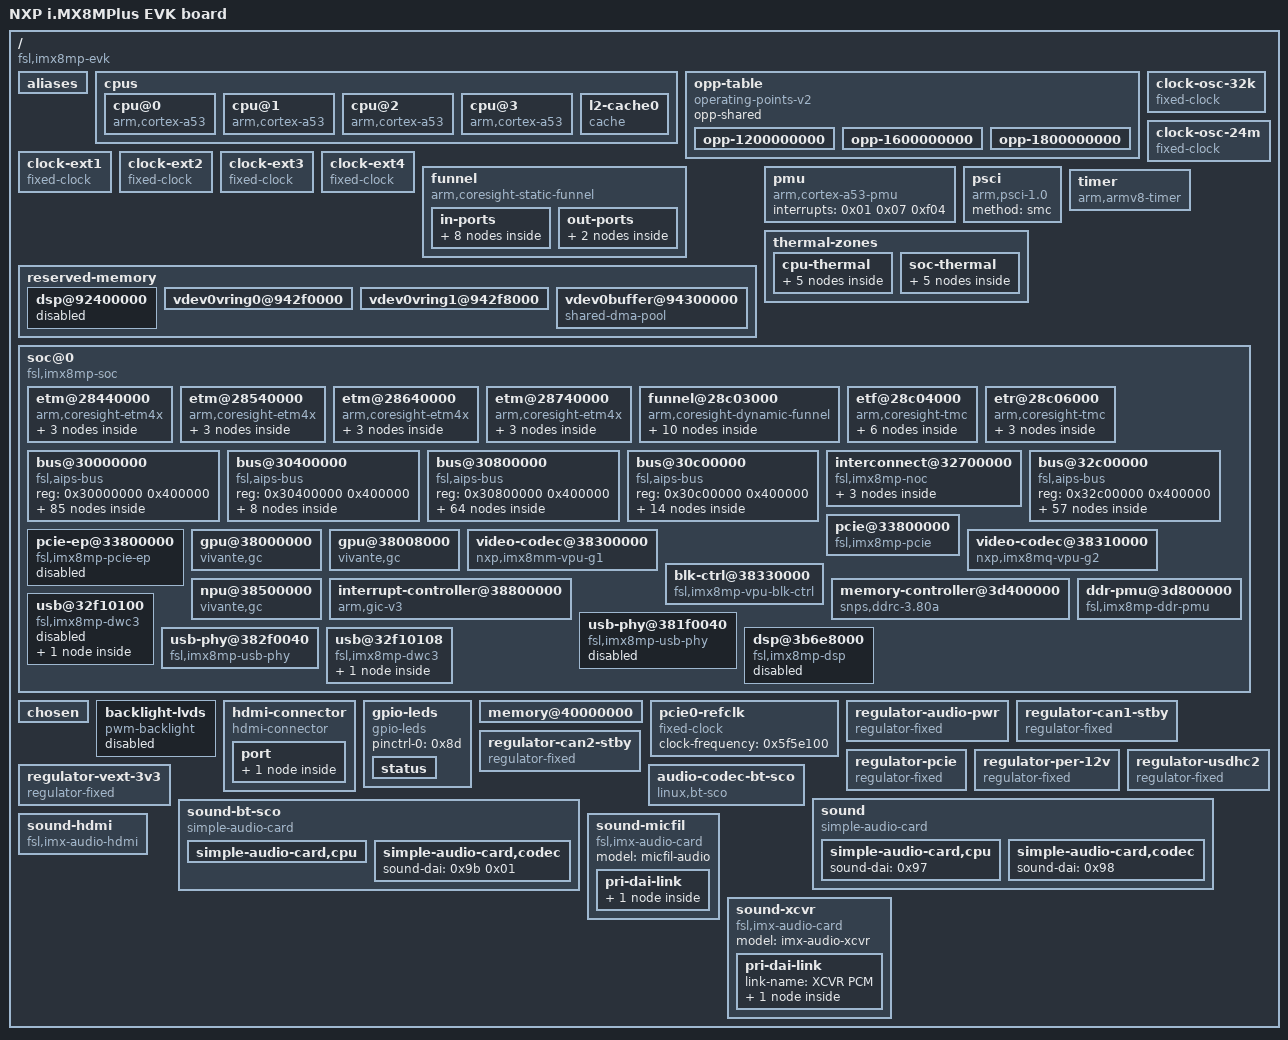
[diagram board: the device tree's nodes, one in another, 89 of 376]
/*
 * Copyright Linux Kernel Team
 *
 * SPDX-License-Identifier: GPL-2.0-only
 *
 * This file is derived from an intermediate build stage of the
 * Linux kernel. The licenses of all input files to this process
 * are compatible with GPL-2.0-only.
 */
/dts-v1/;

/ {
	interrupt-parent = <0x01>;
	#address-cells = <0x02>;
	#size-cells = <0x02>;
	model = "NXP i.MX8MPlus EVK board";
	compatible = "fsl,imx8mp-evk", "fsl,imx8mp";

	aliases {
		ethernet0 = "/soc@0/bus@30800000/ethernet@30be0000";
		ethernet1 = "/soc@0/bus@30800000/ethernet@30bf0000";
		gpio0 = "/soc@0/bus@30000000/gpio@30200000";
		gpio1 = "/soc@0/bus@30000000/gpio@30210000";
		gpio2 = "/soc@0/bus@30000000/gpio@30220000";
		gpio3 = "/soc@0/bus@30000000/gpio@30230000";
		gpio4 = "/soc@0/bus@30000000/gpio@30240000";
		i2c0 = "/soc@0/bus@30800000/i2c@30a20000";
		i2c1 = "/soc@0/bus@30800000/i2c@30a30000";
		i2c2 = "/soc@0/bus@30800000/i2c@30a40000";
		i2c3 = "/soc@0/bus@30800000/i2c@30a50000";
		i2c4 = "/soc@0/bus@30800000/i2c@30ad0000";
		i2c5 = "/soc@0/bus@30800000/i2c@30ae0000";
		mmc0 = "/soc@0/bus@30800000/mmc@30b40000";
		mmc1 = "/soc@0/bus@30800000/mmc@30b50000";
		mmc2 = "/soc@0/bus@30800000/mmc@30b60000";
		serial0 = "/soc@0/bus@30800000/spba-bus@30800000/serial@30860000";
		serial1 = "/soc@0/bus@30800000/spba-bus@30800000/serial@30890000";
		serial2 = "/soc@0/bus@30800000/spba-bus@30800000/serial@30880000";
		serial3 = "/soc@0/bus@30800000/serial@30a60000";
		spi0 = "/soc@0/bus@30800000/spi@30bb0000";
	};

	cpus {
		#address-cells = <0x01>;
		#size-cells = <0x00>;

		cpu@0 {
			device_type = "cpu";
			compatible = "arm,cortex-a53";
			reg = <0x00>;
			clock-latency = <0xee6c>;
			clocks = <0x02 0x11f>;
			enable-method = "psci";
			i-cache-size = <0x8000>;
			i-cache-line-size = <0x40>;
			i-cache-sets = <0x100>;
			d-cache-size = <0x8000>;
			d-cache-line-size = <0x40>;
			d-cache-sets = <0x80>;
			next-level-cache = <0x03>;
			nvmem-cells = <0x04>;
			nvmem-cell-names = "speed_grade";
			operating-points-v2 = <0x05>;
			#cooling-cells = <0x02>;
			cpu-supply = <0x06>;
			phandle = <0x0e>;
		};

		cpu@1 {
			device_type = "cpu";
			compatible = "arm,cortex-a53";
			reg = <0x01>;
			clock-latency = <0xee6c>;
			clocks = <0x02 0x11f>;
			enable-method = "psci";
			i-cache-size = <0x8000>;
			i-cache-line-size = <0x40>;
			i-cache-sets = <0x100>;
			d-cache-size = <0x8000>;
			d-cache-line-size = <0x40>;
			d-cache-sets = <0x80>;
			next-level-cache = <0x03>;
			operating-points-v2 = <0x05>;
			#cooling-cells = <0x02>;
			cpu-supply = <0x06>;
			phandle = <0x0f>;
		};

		cpu@2 {
			device_type = "cpu";
			compatible = "arm,cortex-a53";
			reg = <0x02>;
			clock-latency = <0xee6c>;
			clocks = <0x02 0x11f>;
			enable-method = "psci";
			i-cache-size = <0x8000>;
			i-cache-line-size = <0x40>;
			i-cache-sets = <0x100>;
			d-cache-size = <0x8000>;
			d-cache-line-size = <0x40>;
			d-cache-sets = <0x80>;
			next-level-cache = <0x03>;
			operating-points-v2 = <0x05>;
			#cooling-cells = <0x02>;
			cpu-supply = <0x06>;
			phandle = <0x10>;
		};

		cpu@3 {
			device_type = "cpu";
			compatible = "arm,cortex-a53";
			reg = <0x03>;
			clock-latency = <0xee6c>;
			clocks = <0x02 0x11f>;
			enable-method = "psci";
			i-cache-size = <0x8000>;
			i-cache-line-size = <0x40>;
			i-cache-sets = <0x100>;
			d-cache-size = <0x8000>;
			d-cache-line-size = <0x40>;
			d-cache-sets = <0x80>;
			next-level-cache = <0x03>;
			operating-points-v2 = <0x05>;
			#cooling-cells = <0x02>;
			cpu-supply = <0x06>;
			phandle = <0x11>;
		};

		l2-cache0 {
			compatible = "cache";
			cache-unified;
			cache-level = <0x02>;
			cache-size = <0x80000>;
			cache-line-size = <0x40>;
			cache-sets = <0x200>;
			phandle = <0x03>;
		};
	};

	opp-table {
		compatible = "operating-points-v2";
		opp-shared;
		phandle = <0x05>;

		opp-1200000000 {
			opp-hz = <0x00 0x47868c00>;
			opp-microvolt = <0xcf850>;
			opp-supported-hw = <0x8a0 0x07>;
			clock-latency-ns = <0x249f0>;
			opp-suspend;
		};

		opp-1600000000 {
			opp-hz = <0x00 0x5f5e1000>;
			opp-microvolt = <0xe7ef0>;
			opp-supported-hw = <0xa0 0x07>;
			clock-latency-ns = <0x249f0>;
			opp-suspend;
		};

		opp-1800000000 {
			opp-hz = <0x00 0x6b49d200>;
			opp-microvolt = <0xf4240>;
			opp-supported-hw = <0x20 0x03>;
			clock-latency-ns = <0x249f0>;
			opp-suspend;
		};
	};

	clock-osc-32k {
		compatible = "fixed-clock";
		#clock-cells = <0x00>;
		clock-frequency = <0x8000>;
		clock-output-names = "osc_32k";
		phandle = <0x22>;
	};

	clock-osc-24m {
		compatible = "fixed-clock";
		#clock-cells = <0x00>;
		clock-frequency = <0x16e3600>;
		clock-output-names = "osc_24m";
		phandle = <0x23>;
	};

	clock-ext1 {
		compatible = "fixed-clock";
		#clock-cells = <0x00>;
		clock-frequency = <0x7ed6b40>;
		clock-output-names = "clk_ext1";
		phandle = <0x24>;
	};

	clock-ext2 {
		compatible = "fixed-clock";
		#clock-cells = <0x00>;
		clock-frequency = <0x7ed6b40>;
		clock-output-names = "clk_ext2";
		phandle = <0x25>;
	};

	clock-ext3 {
		compatible = "fixed-clock";
		#clock-cells = <0x00>;
		clock-frequency = <0x7ed6b40>;
		clock-output-names = "clk_ext3";
		phandle = <0x26>;
	};

	clock-ext4 {
		compatible = "fixed-clock";
		#clock-cells = <0x00>;
		clock-frequency = <0x7ed6b40>;
		clock-output-names = "clk_ext4";
		phandle = <0x27>;
	};

	funnel {
		compatible = "arm,coresight-static-funnel";

		in-ports {
			#address-cells = <0x01>;
			#size-cells = <0x00>;

			port@0 {
				reg = <0x00>;

				endpoint {
					remote-endpoint = <0x07>;
					phandle = <0x14>;
				};
			};

			port@1 {
				reg = <0x01>;

				endpoint {
					remote-endpoint = <0x08>;
					phandle = <0x15>;
				};
			};

			port@2 {
				reg = <0x02>;

				endpoint {
					remote-endpoint = <0x09>;
					phandle = <0x16>;
				};
			};

			port@3 {
				reg = <0x03>;

				endpoint {
					remote-endpoint = <0x0a>;
					phandle = <0x17>;
				};
			};
		};

		out-ports {

			port {

				endpoint {
					remote-endpoint = <0x0b>;
					phandle = <0x18>;
				};
			};
		};
	};

	reserved-memory {
		#address-cells = <0x02>;
		#size-cells = <0x02>;
		ranges;

		dsp@92400000 {
			reg = <0x00 0x92400000 0x00 0x2000000>;
			no-map;
			status = "disabled";
			phandle = <0x89>;
		};

		vdev0vring0@942f0000 {
			reg = <0x00 0x942f0000 0x00 0x8000>;
			no-map;
			phandle = <0x9f>;
		};

		vdev0vring1@942f8000 {
			reg = <0x00 0x942f8000 0x00 0x8000>;
			no-map;
			phandle = <0xa0>;
		};

		vdev0buffer@94300000 {
			compatible = "shared-dma-pool";
			reg = <0x00 0x94300000 0x00 0x100000>;
			no-map;
			phandle = <0xa1>;
		};
	};

	pmu {
		compatible = "arm,cortex-a53-pmu";
		interrupts = <0x01 0x07 0xf04>;
	};

	psci {
		compatible = "arm,psci-1.0";
		method = "smc";
	};

	thermal-zones {

		cpu-thermal {
			polling-delay-passive = <0xfa>;
			polling-delay = <0x7d0>;
			thermal-sensors = <0x0c 0x00>;

			trips {

				trip0 {
					temperature = <0x14c08>;
					hysteresis = <0x7d0>;
					type = "passive";
					phandle = <0x0d>;
				};

				trip1 {
					temperature = <0x17318>;
					hysteresis = <0x7d0>;
					type = "critical";
					phandle = <0xa2>;
				};
			};

			cooling-maps {

				map0 {
					trip = <0x0d>;
					cooling-device = <0x0e 0xffffffff 0xffffffff 0x0f 0xffffffff 0xffffffff 0x10 0xffffffff 0xffffffff 0x11 0xffffffff 0xffffffff>;
				};
			};
		};

		soc-thermal {
			polling-delay-passive = <0xfa>;
			polling-delay = <0x7d0>;
			thermal-sensors = <0x0c 0x01>;

			trips {

				trip0 {
					temperature = <0x14c08>;
					hysteresis = <0x7d0>;
					type = "passive";
					phandle = <0x12>;
				};

				trip1 {
					temperature = <0x17318>;
					hysteresis = <0x7d0>;
					type = "critical";
					phandle = <0xa3>;
				};
			};

			cooling-maps {

				map0 {
					trip = <0x12>;
					cooling-device = <0x0e 0xffffffff 0xffffffff 0x0f 0xffffffff 0xffffffff 0x10 0xffffffff 0xffffffff 0x11 0xffffffff 0xffffffff>;
				};
			};
		};
	};

	timer {
		compatible = "arm,armv8-timer";
		interrupts = <0x01 0x0d 0xf08 0x01 0x0e 0xf08 0x01 0x0b 0xf08 0x01 0x0a 0xf08>;
		clock-frequency = <0x7a1200>;
		arm,no-tick-in-suspend;
	};

	soc@0 {
		compatible = "fsl,imx8mp-soc", "simple-bus";
		#address-cells = <0x01>;
		#size-cells = <0x01>;
		ranges = <0x00 0x00 0x00 0x3e000000>;
		nvmem-cells = <0x13>;
		nvmem-cell-names = "soc_unique_id";
		phandle = <0xa4>;

		etm@28440000 {
			compatible = "arm,coresight-etm4x", "arm,primecell";
			reg = <0x28440000 0x1000>;
			cpu = <0x0e>;
			clocks = <0x02 0x5d>;
			clock-names = "apb_pclk";
			phandle = <0xa5>;

			out-ports {

				port {

					endpoint {
						remote-endpoint = <0x14>;
						phandle = <0x07>;
					};
				};
			};
		};

		etm@28540000 {
			compatible = "arm,coresight-etm4x", "arm,primecell";
			reg = <0x28540000 0x1000>;
			cpu = <0x0f>;
			clocks = <0x02 0x5d>;
			clock-names = "apb_pclk";
			phandle = <0xa6>;

			out-ports {

				port {

					endpoint {
						remote-endpoint = <0x15>;
						phandle = <0x08>;
					};
				};
			};
		};

		etm@28640000 {
			compatible = "arm,coresight-etm4x", "arm,primecell";
			reg = <0x28640000 0x1000>;
			cpu = <0x10>;
			clocks = <0x02 0x5d>;
			clock-names = "apb_pclk";
			phandle = <0xa7>;

			out-ports {

				port {

					endpoint {
						remote-endpoint = <0x16>;
						phandle = <0x09>;
					};
				};
			};
		};

		etm@28740000 {
			compatible = "arm,coresight-etm4x", "arm,primecell";
			reg = <0x28740000 0x1000>;
			cpu = <0x11>;
			clocks = <0x02 0x5d>;
			clock-names = "apb_pclk";
			phandle = <0xa8>;

			out-ports {

				port {

					endpoint {
						remote-endpoint = <0x17>;
						phandle = <0x0a>;
					};
				};
			};
		};

		funnel@28c03000 {
			compatible = "arm,coresight-dynamic-funnel", "arm,primecell";
			reg = <0x28c03000 0x1000>;
			clocks = <0x02 0x5d>;
			clock-names = "apb_pclk";

			in-ports {
				#address-cells = <0x01>;
				#size-cells = <0x00>;

				port@0 {
					reg = <0x00>;

					endpoint {
						remote-endpoint = <0x18>;
						phandle = <0x0b>;
					};
				};

				port@1 {
					reg = <0x01>;

					endpoint {
						phandle = <0xa9>;
					};
				};

				port@2 {
					reg = <0x02>;

					endpoint {
						phandle = <0xaa>;
					};
				};
			};

			out-ports {

				port {

					endpoint {
						remote-endpoint = <0x19>;
						phandle = <0x1a>;
					};
				};
			};
		};

		etf@28c04000 {
			compatible = "arm,coresight-tmc", "arm,primecell";
			reg = <0x28c04000 0x1000>;
			clocks = <0x02 0x5d>;
			clock-names = "apb_pclk";

			in-ports {

				port {

					endpoint {
						remote-endpoint = <0x1a>;
						phandle = <0x19>;
					};
				};
			};

			out-ports {

				port {

					endpoint {
						remote-endpoint = <0x1b>;
						phandle = <0x1c>;
					};
				};
			};
		};

		etr@28c06000 {
			compatible = "arm,coresight-tmc", "arm,primecell";
			reg = <0x28c06000 0x1000>;
			clocks = <0x02 0x5d>;
			clock-names = "apb_pclk";

			in-ports {

				port {

					endpoint {
						remote-endpoint = <0x1c>;
						phandle = <0x1b>;
					};
				};
			};
		};

		bus@30000000 {
			compatible = "fsl,aips-bus", "simple-bus";
			reg = <0x30000000 0x400000>;
			#address-cells = <0x01>;
			#size-cells = <0x01>;
			ranges;
			phandle = <0xab>;

			gpio@30200000 {
				compatible = "fsl,imx8mp-gpio", "fsl,imx35-gpio";
				reg = <0x30200000 0x10000>;
				interrupts = <0x00 0x40 0x04 0x00 0x41 0x04>;
				clocks = <0x02 0xc1>;
				gpio-controller;
				#gpio-cells = <0x02>;
				interrupt-controller;
				#interrupt-cells = <0x02>;
				gpio-ranges = <0x1d 0x00 0x05 0x1e>;
				phandle = <0x38>;
			};

			gpio@30210000 {
				compatible = "fsl,imx8mp-gpio", "fsl,imx35-gpio";
				reg = <0x30210000 0x10000>;
				interrupts = <0x00 0x42 0x04 0x00 0x43 0x04>;
				clocks = <0x02 0xc2>;
				gpio-controller;
				#gpio-cells = <0x02>;
				interrupt-controller;
				#interrupt-cells = <0x02>;
				gpio-ranges = <0x1d 0x00 0x23 0x15>;
				phandle = <0x47>;
			};

			gpio@30220000 {
				compatible = "fsl,imx8mp-gpio", "fsl,imx35-gpio";
				reg = <0x30220000 0x10000>;
				interrupts = <0x00 0x44 0x04 0x00 0x45 0x04>;
				clocks = <0x02 0xc3>;
				gpio-controller;
				#gpio-cells = <0x02>;
				interrupt-controller;
				#interrupt-cells = <0x02>;
				gpio-ranges = <0x1d 0x00 0x38 0x1a 0x1d 0x1a 0x90 0x04>;
				phandle = <0x8e>;
			};

			gpio@30230000 {
				compatible = "fsl,imx8mp-gpio", "fsl,imx35-gpio";
				reg = <0x30230000 0x10000>;
				interrupts = <0x00 0x46 0x04 0x00 0x47 0x04>;
				clocks = <0x02 0xc4>;
				gpio-controller;
				#gpio-cells = <0x02>;
				interrupt-controller;
				#interrupt-cells = <0x02>;
				gpio-ranges = <0x1d 0x00 0x52 0x20>;
				phandle = <0x50>;
			};

			gpio@30240000 {
				compatible = "fsl,imx8mp-gpio", "fsl,imx35-gpio";
				reg = <0x30240000 0x10000>;
				interrupts = <0x00 0x48 0x04 0x00 0x49 0x04>;
				clocks = <0x02 0xc5>;
				gpio-controller;
				#gpio-cells = <0x02>;
				interrupt-controller;
				#interrupt-cells = <0x02>;
				gpio-ranges = <0x1d 0x00 0x72 0x1e>;
				phandle = <0x91>;
			};

			tmu@30260000 {
				compatible = "fsl,imx8mp-tmu";
				reg = <0x30260000 0x10000>;
				clocks = <0x02 0x119>;
				nvmem-cells = <0x1e>;
				nvmem-cell-names = "calib";
				#thermal-sensor-cells = <0x01>;
				phandle = <0x0c>;
			};

			watchdog@30280000 {
				compatible = "fsl,imx8mp-wdt", "fsl,imx21-wdt";
				reg = <0x30280000 0x10000>;
				interrupts = <0x00 0x4e 0x04>;
				clocks = <0x02 0x103>;
				status = "okay";
				pinctrl-names = "default";
				pinctrl-0 = <0x1f>;
				fsl,ext-reset-output;
				phandle = <0xac>;
			};

			watchdog@30290000 {
				compatible = "fsl,imx8mp-wdt", "fsl,imx21-wdt";
				reg = <0x30290000 0x10000>;
				interrupts = <0x00 0x4f 0x04>;
				clocks = <0x02 0x104>;
				status = "disabled";
				phandle = <0xad>;
			};

			watchdog@302a0000 {
				compatible = "fsl,imx8mp-wdt", "fsl,imx21-wdt";
				reg = <0x302a0000 0x10000>;
				interrupts = <0x00 0x0a 0x04>;
				clocks = <0x02 0x105>;
				status = "disabled";
				phandle = <0xae>;
			};

			timer@302d0000 {
				compatible = "fsl,imx8mp-gpt", "fsl,imx6dl-gpt";
				reg = <0x302d0000 0x10000>;
				interrupts = <0x00 0x37 0x04>;
				clocks = <0x02 0xc6 0x02 0x9b>;
				clock-names = "ipg", "per";
				phandle = <0xaf>;
			};

			timer@302e0000 {
				compatible = "fsl,imx8mp-gpt", "fsl,imx6dl-gpt";
				reg = <0x302e0000 0x10000>;
				interrupts = <0x00 0x36 0x04>;
				clocks = <0x02 0xc7 0x02 0x9c>;
				clock-names = "ipg", "per";
				phandle = <0xb0>;
			};

			timer@302f0000 {
				compatible = "fsl,imx8mp-gpt", "fsl,imx6dl-gpt";
				reg = <0x302f0000 0x10000>;
				interrupts = <0x00 0x35 0x04>;
				clocks = <0x02 0xc8 0x02 0x9d>;
				clock-names = "ipg", "per";
				phandle = <0xb1>;
			};

			pinctrl@30330000 {
				compatible = "fsl,imx8mp-iomuxc";
				reg = <0x30330000 0x10000>;
				pinctrl-names = "default";
				pinctrl-0 = <0x20>;
				phandle = <0x1d>;

				audiopwrreggrp {
					fsl,pins = <0x1bc 0x41c 0x00 0x05 0x00 0xd6>;
					phandle = <0x8f>;
				};

				eqosgrp {
					fsl,pins = <0x54 0x2b4 0x00 0x00 0x00 0x02 0x58 0x2b8 0x590 0x00 0x01 0x02 0x7c 0x2dc 0x00 0x00 0x00 0x90 0x80 0x2e0 0x00 0x00 0x00 0x90 0x84 0x2e4 0x00 0x00 0x00 0x90 0x88 0x2e8 0x00 0x00 0x00 0x90 0x78 0x2d8 0x00 0x00 0x00 0x90 0x74 0x2d4 0x00 0x00 0x00 0x90 0x68 0x2c8 0x00 0x00 0x00 0x16 0x64 0x2c4 0x00 0x00 0x00 0x16 0x60 0x2c0 0x00 0x00 0x00 0x16 0x5c 0x2bc 0x00 0x00 0x00 0x16 0x6c 0x2cc 0x00 0x00 0x00 0x16 0x70 0x2d0 0x00 0x00 0x00 0x16 0x1a0 0x400 0x00 0x05 0x00 0x10>;
					phandle = <0x52>;
				};

				fecgrp {
					fsl,pins = <0x158 0x3b8 0x00 0x04 0x00 0x02 0x15c 0x3bc 0x57c 0x04 0x01 0x02 0x160 0x3c0 0x580 0x04 0x01 0x90 0x164 0x3c4 0x584 0x04 0x01 0x90 0x168 0x3c8 0x00 0x04 0x00 0x90 0x16c 0x3cc 0x00 0x04 0x00 0x90 0x174 0x3d4 0x00 0x04 0x00 0x90 0x170 0x3d0 0x588 0x04 0x01 0x90 0x178 0x3d8 0x00 0x04 0x00 0x16 0x17c 0x3dc 0x00 0x04 0x00 0x16 0x180 0x3e0 0x00 0x04 0x00 0x16 0x184 0x3e4 0x00 0x04 0x00 0x16 0x188 0x3e8 0x00 0x04 0x00 0x16 0x18c 0x3ec 0x00 0x04 0x00 0x16 0x150 0x3b0 0x00 0x05 0x00 0x10>;
					phandle = <0x4e>;
				};

				flexcan1grp {
					fsl,pins = <0x1d8 0x438 0x54c 0x04 0x02 0x154 0x1d4 0x434 0x00 0x04 0x00 0x154>;
					phandle = <0x32>;
				};

				flexcan2grp {
					fsl,pins = <0x144 0x3a4 0x550 0x06 0x00 0x154 0x140 0x3a0 0x00 0x06 0x00 0x154>;
					phandle = <0x34>;
				};

				flexcan1reggrp {
					fsl,pins = <0x1dc 0x43c 0x00 0x05 0x00 0x154>;
					phandle = <0x90>;
				};

				flexcan2reggrp {
					fsl,pins = <0x1b4 0x414 0x00 0x05 0x00 0x154>;
					phandle = <0x92>;
				};

				flexspi0grp {
					fsl,pins = <0xe0 0x340 0x00 0x01 0x00 0x1c2 0xe4 0x344 0x00 0x01 0x00 0x82 0xf8 0x358 0x00 0x01 0x00 0x82 0xfc 0x35c 0x00 0x01 0x00 0x82 0x100 0x360 0x00 0x01 0x00 0x82 0x104 0x364 0x00 0x01 0x00 0x82>;
					phandle = <0x4c>;
				};

				gpioledgrp {
					fsl,pins = <0x120 0x380 0x00 0x05 0x00 0x140>;
					phandle = <0x8d>;
				};

				hoggrp {
					fsl,pins = <0x24c 0x4ac 0x00 0x00 0x00 0x40000010>;
					phandle = <0x20>;
				};

				i2c1grp {
					fsl,pins = <0x200 0x460 0x5a4 0x00 0x02 0x400001c2 0x204 0x464 0x5a8 0x00 0x02 0x400001c2>;
					phandle = <0x36>;
				};

				i2c2grp {
					fsl,pins = <0x208 0x468 0x5ac 0x00 0x02 0x400001c2 0x20c 0x46c 0x5b0 0x00 0x02 0x400001c2>;
					phandle = <0x39>;
				};

				i2c3grp {
					fsl,pins = <0x210 0x470 0x5b4 0x00 0x04 0x400001c2 0x214 0x474 0x5b8 0x00 0x04 0x400001c2>;
					phandle = <0x3e>;
				};

				i2c5grp {
					fsl,pins = <0x1d8 0x438 0x5c8 0x02 0x02 0x400001c2 0x1d4 0x434 0x5c4 0x02 0x02 0x400001c2>;
					phandle = <0x42>;
				};

				pcie0grp {
					fsl,pins = <0x218 0x478 0x5a0 0x02 0x00 0x60 0xa8 0x308 0x00 0x05 0x00 0x40>;
					phandle = <0x7c>;
				};

				pcie0reggrp {
					fsl,pins = <0xa4 0x304 0x00 0x05 0x00 0x40>;
					phandle = <0x93>;
				};

				pdmgrp {
					fsl,pins = <0x130 0x390 0x00 0x04 0x00 0xd6 0x134 0x394 0x4c0 0x04 0x03 0xd6 0x138 0x398 0x4c4 0x04 0x03 0xd6 0x13c 0x39c 0x4c8 0x04 0x03 0xd6 0x140 0x3a0 0x4cc 0x04 0x03 0xd6>;
					phandle = <0x59>;
				};

				pmicgrp {
					fsl,pins = <0x20 0x280 0x00 0x00 0x00 0x1c0>;
					phandle = <0x37>;
				};

				pca6416_int_grp {
					fsl,pins = <0x44 0x2a4 0x00 0x00 0x00 0x146>;
					phandle = <0x41>;
				};

				pwm1grp {
					fsl,pins = <0x18 0x278 0x00 0x01 0x00 0x116>;
					phandle = <0x2a>;
				};

				pwm2grp {
					fsl,pins = <0x40 0x2a0 0x00 0x02 0x00 0x116>;
					phandle = <0x2b>;
				};

				pwm4grp {
					fsl,pins = <0x12c 0x38c 0x00 0x02 0x00 0x116>;
					phandle = <0x2c>;
				};

				regusdhc2vmmcgrp {
					fsl,pins = <0xd8 0x338 0x00 0x05 0x00 0x40>;
					phandle = <0x95>;
				};

				uart1grp {
					fsl,pins = <0x220 0x480 0x5e8 0x00 0x04 0x140 0x224 0x484 0x00 0x00 0x00 0x140 0x230 0x490 0x00 0x01 0x00 0x140 0x234 0x494 0x5e4 0x01 0x05 0x140>;
					phandle = <0x2e>;
				};

				sai2grp {
					fsl,pins = <0x1ac 0x40c 0x00 0x00 0x00 0xd6 0x1a8 0x408 0x00 0x00 0x00 0xd6 0x1b0 0x410 0x00 0x00 0x00 0xd6 0x1a4 0x404 0x00 0x00 0x00 0xd6>;
					phandle = <0x57>;
				};

				sai3grp {
					fsl,pins = <0x1c4 0x424 0x4ec 0x00 0x01 0xd6 0x1c8 0x428 0x4e8 0x00 0x01 0xd6 0x1c0 0x420 0x4e4 0x00 0x01 0xd6 0x1cc 0x42c 0x00 0x00 0x00 0xd6 0x1d0 0x430 0x4e0 0x00 0x02 0xd6>;
					phandle = <0x58>;
				};

				uart2grp {
					fsl,pins = <0x228 0x488 0x5f0 0x00 0x06 0x140 0x22c 0x48c 0x00 0x00 0x00 0x140>;
					phandle = <0x30>;
				};

				usb1grp {
					fsl,pins = <0x4c 0x2ac 0x00 0x01 0x00 0x10>;
					phandle = <0x87>;
				};

				uart3grp {
					fsl,pins = <0x1e0 0x440 0x5f8 0x01 0x04 0x140 0x1e4 0x444 0x00 0x01 0x00 0x140 0x1ec 0x44c 0x5f4 0x01 0x03 0x140 0x1e8 0x448 0x00 0x01 0x00 0x140>;
					phandle = <0x2f>;
				};

				usdhc2grp {
					fsl,pins = <0xc0 0x320 0x00 0x00 0x00 0x190 0xc4 0x324 0x00 0x00 0x00 0x1d0 0xc8 0x328 0x00 0x00 0x00 0x1d0 0xcc 0x32c 0x00 0x00 0x00 0x1d0 0xd0 0x330 0x00 0x00 0x00 0x1d0 0xd4 0x334 0x00 0x00 0x00 0x1d0 0x24 0x284 0x00 0x01 0x00 0xc0>;
					phandle = <0x43>;
				};

				usdhc2-100mhzgrp {
					fsl,pins = <0xc0 0x320 0x00 0x00 0x00 0x194 0xc4 0x324 0x00 0x00 0x00 0x1d4 0xc8 0x328 0x00 0x00 0x00 0x1d4 0xcc 0x32c 0x00 0x00 0x00 0x1d4 0xd0 0x330 0x00 0x00 0x00 0x1d4 0xd4 0x334 0x00 0x00 0x00 0x1d4 0x24 0x284 0x00 0x01 0x00 0xc0>;
					phandle = <0x45>;
				};

				usdhc2-200mhzgrp {
					fsl,pins = <0xc0 0x320 0x00 0x00 0x00 0x196 0xc4 0x324 0x00 0x00 0x00 0x1d6 0xc8 0x328 0x00 0x00 0x00 0x1d6 0xcc 0x32c 0x00 0x00 0x00 0x1d6 0xd0 0x330 0x00 0x00 0x00 0x1d6 0xd4 0x334 0x00 0x00 0x00 0x1d6 0x24 0x284 0x00 0x01 0x00 0xc0>;
					phandle = <0x46>;
				};

				usdhc2gpiogrp {
					fsl,pins = <0xbc 0x31c 0x00 0x05 0x00 0x1c4>;
					phandle = <0x44>;
				};

				usdhc3grp {
					fsl,pins = <0x124 0x384 0x604 0x02 0x01 0x190 0x128 0x388 0x60c 0x02 0x01 0x1d0 0x108 0x368 0x610 0x02 0x01 0x1d0 0x10c 0x36c 0x614 0x02 0x01 0x1d0 0x110 0x370 0x618 0x02 0x01 0x1d0 0x114 0x374 0x61c 0x02 0x01 0x1d0 0x11c 0x37c 0x620 0x02 0x01 0x1d0 0xec 0x34c 0x624 0x02 0x01 0x1d0 0xf0 0x350 0x628 0x02 0x01 0x1d0 0xf4 0x354 0x62c 0x02 0x01 0x1d0 0xe8 0x348 0x630 0x02 0x01 0x190>;
					phandle = <0x49>;
				};

				usdhc3-100mhzgrp {
					fsl,pins = <0x124 0x384 0x604 0x02 0x01 0x194 0x128 0x388 0x60c 0x02 0x01 0x1d4 0x108 0x368 0x610 0x02 0x01 0x1d4 0x10c 0x36c 0x614 0x02 0x01 0x1d4 0x110 0x370 0x618 0x02 0x01 0x1d4 0x114 0x374 0x61c 0x02 0x01 0x1d4 0x11c 0x37c 0x620 0x02 0x01 0x1d4 0xec 0x34c 0x624 0x02 0x01 0x1d4 0xf0 0x350 0x628 0x02 0x01 0x1d4 0xf4 0x354 0x62c 0x02 0x01 0x1d4 0xe8 0x348 0x630 0x02 0x01 0x194>;
					phandle = <0x4a>;
				};

				usdhc3-200mhzgrp {
					fsl,pins = <0x124 0x384 0x604 0x02 0x01 0x196 0x128 0x388 0x60c 0x02 0x01 0x1d6 0x108 0x368 0x610 0x02 0x01 0x1d6 0x10c 0x36c 0x614 0x02 0x01 0x1d6 0x110 0x370 0x618 0x02 0x01 0x1d6 0x114 0x374 0x61c 0x02 0x01 0x1d6 0x11c 0x37c 0x620 0x02 0x01 0x1d6 0xec 0x34c 0x624 0x02 0x01 0x1d6 0xf0 0x350 0x628 0x02 0x01 0x1d6 0xf4 0x354 0x62c 0x02 0x01 0x1d6 0xe8 0x348 0x630 0x02 0x01 0x196>;
					phandle = <0x4b>;
				};

				wdoggrp {
					fsl,pins = <0x1c 0x27c 0x00 0x01 0x00 0x166>;
					phandle = <0x1f>;
				};
			};

			syscon@30340000 {
				compatible = "fsl,imx8mp-iomuxc-gpr", "syscon";
				reg = <0x30340000 0x10000>;
				phandle = <0x31>;
			};

			efuse@30350000 {
				compatible = "fsl,imx8mp-ocotp", "fsl,imx8mm-ocotp", "syscon";
				reg = <0x30350000 0x10000>;
				clocks = <0x02 0xd6>;
				#address-cells = <0x01>;
				#size-cells = <0x01>;
				phandle = <0xb2>;

				unique-id@8 {
					reg = <0x08 0x08>;
					phandle = <0x13>;
				};

				speed-grade@10 {
					reg = <0x10 0x04>;
					phandle = <0x04>;
				};

				mac-address@90 {
					reg = <0x90 0x06>;
					phandle = <0x4d>;
				};

				mac-address@96 {
					reg = <0x96 0x06>;
					phandle = <0x51>;
				};

				calib@264 {
					reg = <0x264 0x10>;
					phandle = <0x1e>;
				};
			};

			clock-controller@30360000 {
				compatible = "fsl,imx8mp-anatop", "fsl,imx8mm-anatop";
				reg = <0x30360000 0x10000>;
				#clock-cells = <0x01>;
				phandle = <0xb3>;
			};

			snvs@30370000 {
				compatible = "fsl,sec-v4.0-mon", "syscon", "simple-mfd";
				reg = <0x30370000 0x10000>;
				phandle = <0x21>;

				snvs-rtc-lp {
					compatible = "fsl,sec-v4.0-mon-rtc-lp";
					regmap = <0x21>;
					offset = <0x34>;
					interrupts = <0x00 0x13 0x04 0x00 0x14 0x04>;
					clocks = <0x02 0xf9>;
					clock-names = "snvs-rtc";
					phandle = <0xb4>;
				};

				snvs-powerkey {
					compatible = "fsl,sec-v4.0-pwrkey";
					regmap = <0x21>;
					interrupts = <0x00 0x04 0x04>;
					clocks = <0x02 0xf9>;
					clock-names = "snvs-pwrkey";
					linux,keycode = <0x74>;
					wakeup-source;
					status = "okay";
					phandle = <0xb5>;
				};

				snvs-lpgpr {
					compatible = "fsl,imx8mp-snvs-lpgpr", "fsl,imx7d-snvs-lpgpr";
					phandle = <0xb6>;
				};
			};

			clock-controller@30380000 {
				compatible = "fsl,imx8mp-ccm";
				reg = <0x30380000 0x10000>;
				interrupts = <0x00 0x55 0x04 0x00 0x56 0x04>;
				#clock-cells = <0x01>;
				clocks = <0x22 0x23 0x24 0x25 0x26 0x27>;
				clock-names = "osc_32k", "osc_24m", "clk_ext1", "clk_ext2", "clk_ext3", "clk_ext4";
				assigned-clocks = <0x02 0x42 0x02 0x120 0x02 0x67 0x02 0x68 0x02 0x94>;
				assigned-clock-parents = <0x02 0x38 0x02 0x2c 0x02 0x41 0x02 0x38 0x02 0x40>;
				assigned-clock-rates = <0x00 0x00 0x3b9aca00 0x2faf0800 0x1dcd6500>;
				phandle = <0x02>;
			};

			reset-controller@30390000 {
				compatible = "fsl,imx8mp-src", "syscon";
				reg = <0x30390000 0x10000>;
				interrupts = <0x00 0x59 0x04>;
				#reset-cells = <0x01>;
				phandle = <0x6b>;
			};

			gpc@303a0000 {
				compatible = "fsl,imx8mp-gpc";
				reg = <0x303a0000 0x1000>;
				interrupt-parent = <0x01>;
				interrupts = <0x00 0x57 0x04>;
				interrupt-controller;
				#interrupt-cells = <0x03>;
				phandle = <0xb7>;

				pgc {
					#address-cells = <0x01>;
					#size-cells = <0x00>;

					power-domain@0 {
						#power-domain-cells = <0x00>;
						reg = <0x00>;
						phandle = <0x66>;
					};

					power-domain@1 {
						#power-domain-cells = <0x00>;
						reg = <0x01>;
						phandle = <0x71>;
					};

					power-domain@2 {
						#power-domain-cells = <0x00>;
						reg = <0x02>;
						phandle = <0x6f>;
					};

					power-domain@3 {
						#power-domain-cells = <0x00>;
						reg = <0x03>;
						phandle = <0x70>;
					};

					power-domain@4 {
						#power-domain-cells = <0x00>;
						reg = <0x04>;
						clocks = <0x02 0x69 0x02 0x6a 0x02 0x10b>;
						assigned-clocks = <0x02 0x132 0x02 0x69 0x02 0x6a>;
						assigned-clock-parents = <0x02 0x38 0x02 0x38 0x02 0x38>;
						assigned-clock-rates = <0x2faf0800 0x2faf0800 0x11e1a300>;
						phandle = <0x84>;
					};

					power-domain@5 {
						#power-domain-cells = <0x00>;
						reg = <0x05>;
						clocks = <0x02 0x11c 0x02 0x136>;
						assigned-clocks = <0x02 0x6c 0x02 0x48>;
						assigned-clock-parents = <0x02 0x38 0x02 0x38>;
						assigned-clock-rates = <0x17d78400 0x23c34600>;
						phandle = <0x5a>;
					};

					power-domain@6 {
						#power-domain-cells = <0x00>;
						reg = <0x06>;
						clocks = <0x02 0xf7>;
						power-domains = <0x28>;
						phandle = <0x7f>;
					};

					power-domain@7 {
						#power-domain-cells = <0x00>;
						reg = <0x07>;
						clocks = <0x02 0x107 0x02 0x66>;
						assigned-clocks = <0x02 0x65 0x02 0x66>;
						assigned-clock-parents = <0x02 0x38 0x02 0x38>;
						assigned-clock-rates = <0x2faf0800 0x17d78400>;
						phandle = <0x28>;
					};

					power-domain@8 {
						#power-domain-cells = <0x00>;
						reg = <0x08>;
						clocks = <0x02 0x11a>;
						phandle = <0x29>;
					};

					power-domain@9 {
						#power-domain-cells = <0x00>;
						reg = <0x09>;
						clocks = <0x02 0xf8 0x02 0x134>;
						power-domains = <0x28>;
						phandle = <0x7e>;
					};

					power-domain@10 {
						#power-domain-cells = <0x00>;
						reg = <0x0a>;
						clocks = <0x02 0x10e 0x02 0x10d>;
						phandle = <0x65>;
					};

					power-domain@11 {
						#power-domain-cells = <0x00>;
						power-domains = <0x29>;
						reg = <0x0b>;
						clocks = <0x02 0x106>;
						phandle = <0x81>;
					};

					power-domain@12 {
						#power-domain-cells = <0x00>;
						power-domains = <0x29>;
						reg = <0x0c>;
						clocks = <0x02 0x10a>;
						phandle = <0x82>;
					};

					power-domain@13 {
						#power-domain-cells = <0x00>;
						power-domains = <0x29>;
						reg = <0x0d>;
						clocks = <0x02 0x109>;
						phandle = <0x83>;
					};

					power-domain@14 {
						#power-domain-cells = <0x00>;
						reg = <0x0e>;
						clocks = <0x02 0x116 0x02 0x63>;
						assigned-clocks = <0x02 0x64 0x02 0x63>;
						assigned-clock-parents = <0x02 0x40 0x02 0x33>;
						assigned-clock-rates = <0x1dcd6500 0x7ed6b40>;
						phandle = <0x72>;
					};

					power-domain@15 {
						#power-domain-cells = <0x00>;
						reg = <0x0f>;
						phandle = <0x73>;
					};

					power-domain@16 {
						#power-domain-cells = <0x00>;
						reg = <0x10>;
						phandle = <0x67>;
					};

					power-domain@17 {
						#power-domain-cells = <0x00>;
						reg = <0x11>;
						clocks = <0x02 0x137 0x02 0x10c>;
						assigned-clocks = <0x02 0x137>;
						assigned-clock-parents = <0x02 0x40>;
						assigned-clock-rates = <0x1dcd6500>;
						phandle = <0x6e>;
					};

					power-domain@18 {
						#power-domain-cells = <0x00>;
						reg = <0x12>;
						clocks = <0x02 0x114>;
						phandle = <0x68>;
					};
				};
			};
		};

		bus@30400000 {
			compatible = "fsl,aips-bus", "simple-bus";
			reg = <0x30400000 0x400000>;
			#address-cells = <0x01>;
			#size-cells = <0x01>;
			ranges;
			phandle = <0xb8>;

			pwm@30660000 {
				compatible = "fsl,imx8mp-pwm", "fsl,imx27-pwm";
				reg = <0x30660000 0x10000>;
				interrupts = <0x00 0x51 0x04>;
				clocks = <0x02 0xdc 0x02 0xdc>;
				clock-names = "ipg", "per";
				#pwm-cells = <0x03>;
				status = "okay";
				pinctrl-names = "default";
				pinctrl-0 = <0x2a>;
				phandle = <0xb9>;
			};

			pwm@30670000 {
				compatible = "fsl,imx8mp-pwm", "fsl,imx27-pwm";
				reg = <0x30670000 0x10000>;
				interrupts = <0x00 0x52 0x04>;
				clocks = <0x02 0xdd 0x02 0xdd>;
				clock-names = "ipg", "per";
				#pwm-cells = <0x03>;
				status = "okay";
				pinctrl-names = "default";
				pinctrl-0 = <0x2b>;
				phandle = <0x8a>;
			};

			pwm@30680000 {
				compatible = "fsl,imx8mp-pwm", "fsl,imx27-pwm";
				reg = <0x30680000 0x10000>;
				interrupts = <0x00 0x53 0x04>;
				clocks = <0x02 0xde 0x02 0xde>;
				clock-names = "ipg", "per";
				#pwm-cells = <0x03>;
				status = "disabled";
				phandle = <0xba>;
			};

			pwm@30690000 {
				compatible = "fsl,imx8mp-pwm", "fsl,imx27-pwm";
				reg = <0x30690000 0x10000>;
				interrupts = <0x00 0x54 0x04>;
				clocks = <0x02 0xdf 0x02 0xdf>;
				clock-names = "ipg", "per";
				#pwm-cells = <0x03>;
				status = "okay";
				pinctrl-names = "default";
				pinctrl-0 = <0x2c>;
				phandle = <0xbb>;
			};

			timer@306a0000 {
				compatible = "nxp,sysctr-timer";
				reg = <0x306a0000 0x20000>;
				interrupts = <0x00 0x2f 0x04>;
				clocks = <0x23>;
				clock-names = "per";
				phandle = <0xbc>;
			};

			timer@306e0000 {
				compatible = "fsl,imx8mp-gpt", "fsl,imx6dl-gpt";
				reg = <0x306e0000 0x10000>;
				interrupts = <0x00 0x33 0x04>;
				clocks = <0x02 0xcb 0x02 0xa0>;
				clock-names = "ipg", "per";
				phandle = <0xbd>;
			};

			timer@306f0000 {
				compatible = "fsl,imx8mp-gpt", "fsl,imx6dl-gpt";
				reg = <0x306f0000 0x10000>;
				interrupts = <0x00 0x33 0x04>;
				clocks = <0x02 0xca 0x02 0x9f>;
				clock-names = "ipg", "per";
				phandle = <0xbe>;
			};

			timer@30700000 {
				compatible = "fsl,imx8mp-gpt", "fsl,imx6dl-gpt";
				reg = <0x30700000 0x10000>;
				interrupts = <0x00 0x34 0x04>;
				clocks = <0x02 0xc9 0x02 0x9e>;
				clock-names = "ipg", "per";
				phandle = <0xbf>;
			};
		};

		bus@30800000 {
			compatible = "fsl,aips-bus", "simple-bus";
			reg = <0x30800000 0x400000>;
			#address-cells = <0x01>;
			#size-cells = <0x01>;
			ranges;
			phandle = <0xc0>;

			spba-bus@30800000 {
				compatible = "fsl,spba-bus", "simple-bus";
				reg = <0x30800000 0x100000>;
				#address-cells = <0x01>;
				#size-cells = <0x01>;
				ranges;

				spi@30820000 {
					#address-cells = <0x01>;
					#size-cells = <0x00>;
					compatible = "fsl,imx8mp-ecspi", "fsl,imx6ul-ecspi";
					reg = <0x30820000 0x10000>;
					interrupts = <0x00 0x1f 0x04>;
					clocks = <0x02 0xbd 0x02 0xbd>;
					clock-names = "ipg", "per";
					assigned-clock-rates = <0x4c4b400>;
					assigned-clocks = <0x02 0x95>;
					assigned-clock-parents = <0x02 0x38>;
					dmas = <0x2d 0x00 0x07 0x01 0x2d 0x01 0x07 0x02>;
					dma-names = "rx", "tx";
					status = "disabled";
					phandle = <0xc1>;
				};

				spi@30830000 {
					#address-cells = <0x01>;
					#size-cells = <0x00>;
					compatible = "fsl,imx8mp-ecspi", "fsl,imx6ul-ecspi";
					reg = <0x30830000 0x10000>;
					interrupts = <0x00 0x20 0x04>;
					clocks = <0x02 0xbe 0x02 0xbe>;
					clock-names = "ipg", "per";
					assigned-clock-rates = <0x4c4b400>;
					assigned-clocks = <0x02 0x96>;
					assigned-clock-parents = <0x02 0x38>;
					dmas = <0x2d 0x02 0x07 0x01 0x2d 0x03 0x07 0x02>;
					dma-names = "rx", "tx";
					status = "disabled";
					phandle = <0xc2>;
				};

				spi@30840000 {
					#address-cells = <0x01>;
					#size-cells = <0x00>;
					compatible = "fsl,imx8mp-ecspi", "fsl,imx6ul-ecspi";
					reg = <0x30840000 0x10000>;
					interrupts = <0x00 0x21 0x04>;
					clocks = <0x02 0xbf 0x02 0xbf>;
					clock-names = "ipg", "per";
					assigned-clock-rates = <0x4c4b400>;
					assigned-clocks = <0x02 0xb3>;
					assigned-clock-parents = <0x02 0x38>;
					dmas = <0x2d 0x04 0x07 0x01 0x2d 0x05 0x07 0x02>;
					dma-names = "rx", "tx";
					status = "disabled";
					phandle = <0xc3>;
				};

				serial@30860000 {
					compatible = "fsl,imx8mp-uart", "fsl,imx6q-uart";
					reg = <0x30860000 0x10000>;
					interrupts = <0x00 0x1a 0x04>;
					clocks = <0x02 0xfb 0x02 0xfb>;
					clock-names = "ipg", "per";
					dmas = <0x2d 0x16 0x04 0x00 0x2d 0x17 0x04 0x00>;
					dma-names = "rx", "tx";
					status = "okay";
					pinctrl-names = "default";
					pinctrl-0 = <0x2e>;
					assigned-clocks = <0x02 0x8e>;
					assigned-clock-parents = <0x02 0x31>;
					uart-has-rtscts;
					phandle = <0xc4>;
				};

				serial@30880000 {
					compatible = "fsl,imx8mp-uart", "fsl,imx6q-uart";
					reg = <0x30880000 0x10000>;
					interrupts = <0x00 0x1c 0x04>;
					clocks = <0x02 0xfd 0x02 0xfd>;
					clock-names = "ipg", "per";
					dmas = <0x2d 0x1a 0x04 0x00 0x2d 0x1b 0x04 0x00>;
					dma-names = "rx", "tx";
					status = "okay";
					pinctrl-names = "default";
					pinctrl-0 = <0x2f>;
					assigned-clocks = <0x02 0x90>;
					assigned-clock-parents = <0x02 0x31>;
					uart-has-rtscts;
					phandle = <0xc5>;
				};

				serial@30890000 {
					compatible = "fsl,imx8mp-uart", "fsl,imx6q-uart";
					reg = <0x30890000 0x10000>;
					interrupts = <0x00 0x1b 0x04>;
					clocks = <0x02 0xfc 0x02 0xfc>;
					clock-names = "ipg", "per";
					dmas = <0x2d 0x18 0x04 0x00 0x2d 0x19 0x04 0x00>;
					dma-names = "rx", "tx";
					status = "okay";
					pinctrl-names = "default";
					pinctrl-0 = <0x30>;
					phandle = <0xc6>;
				};

				can@308c0000 {
					compatible = "fsl,imx8mp-flexcan";
					reg = <0x308c0000 0x10000>;
					interrupts = <0x00 0x8e 0x04>;
					clocks = <0x02 0x6e 0x02 0xe9>;
					clock-names = "ipg", "per";
					assigned-clocks = <0x02 0x74>;
					assigned-clock-parents = <0x02 0x30>;
					assigned-clock-rates = <0x2625a00>;
					fsl,clk-source = [00];
					fsl,stop-mode = <0x31 0x10 0x04>;
					status = "okay";
					pinctrl-names = "default";
					pinctrl-0 = <0x32>;
					xceiver-supply = <0x33>;
					phandle = <0xc7>;
				};

				can@308d0000 {
					compatible = "fsl,imx8mp-flexcan";
					reg = <0x308d0000 0x10000>;
					interrupts = <0x00 0x90 0x04>;
					clocks = <0x02 0x6e 0x02 0xea>;
					clock-names = "ipg", "per";
					assigned-clocks = <0x02 0x75>;
					assigned-clock-parents = <0x02 0x30>;
					assigned-clock-rates = <0x2625a00>;
					fsl,clk-source = [00];
					fsl,stop-mode = <0x31 0x10 0x05>;
					status = "disabled";
					pinctrl-names = "default";
					pinctrl-0 = <0x34>;
					xceiver-supply = <0x35>;
					phandle = <0xc8>;
				};
			};

			crypto@30900000 {
				compatible = "fsl,sec-v4.0";
				#address-cells = <0x01>;
				#size-cells = <0x01>;
				reg = <0x30900000 0x40000>;
				ranges = <0x00 0x30900000 0x40000>;
				interrupts = <0x00 0x5b 0x04>;
				clocks = <0x02 0x6b 0x02 0x6e>;
				clock-names = "aclk", "ipg";
				phandle = <0xc9>;

				jr@1000 {
					compatible = "fsl,sec-v4.0-job-ring";
					reg = <0x1000 0x1000>;
					interrupts = <0x00 0x69 0x04>;
					status = "disabled";
					phandle = <0xca>;
				};

				jr@2000 {
					compatible = "fsl,sec-v4.0-job-ring";
					reg = <0x2000 0x1000>;
					interrupts = <0x00 0x6a 0x04>;
					phandle = <0xcb>;
				};

				jr@3000 {
					compatible = "fsl,sec-v4.0-job-ring";
					reg = <0x3000 0x1000>;
					interrupts = <0x00 0x72 0x04>;
					phandle = <0xcc>;
				};
			};

			i2c@30a20000 {
				compatible = "fsl,imx8mp-i2c", "fsl,imx21-i2c";
				#address-cells = <0x01>;
				#size-cells = <0x00>;
				reg = <0x30a20000 0x10000>;
				interrupts = <0x00 0x23 0x04>;
				clocks = <0x02 0xcd>;
				status = "okay";
				clock-frequency = <0x61a80>;
				pinctrl-names = "default";
				pinctrl-0 = <0x36>;
				phandle = <0xcd>;

				pmic@25 {
					compatible = "nxp,pca9450c";
					reg = <0x25>;
					pinctrl-names = "default";
					pinctrl-0 = <0x37>;
					interrupt-parent = <0x38>;
					interrupts = <0x03 0x08>;

					regulators {

						BUCK1 {
							regulator-name = "BUCK1";
							regulator-min-microvolt = <0xafc80>;
							regulator-max-microvolt = <0xf4240>;
							regulator-boot-on;
							regulator-always-on;
							regulator-ramp-delay = <0xc35>;
						};

						BUCK2 {
							regulator-name = "BUCK2";
							regulator-min-microvolt = <0xafc80>;
							regulator-max-microvolt = <0xfa3e8>;
							regulator-boot-on;
							regulator-always-on;
							regulator-ramp-delay = <0xc35>;
							nxp,dvs-run-voltage = <0xe7ef0>;
							nxp,dvs-standby-voltage = <0xcf850>;
							phandle = <0x06>;
						};

						BUCK4 {
							regulator-name = "BUCK4";
							regulator-min-microvolt = <0x2dc6c0>;
							regulator-max-microvolt = <0x36ee80>;
							regulator-boot-on;
							regulator-always-on;
						};

						BUCK5 {
							regulator-name = "BUCK5";
							regulator-min-microvolt = <0x192d50>;
							regulator-max-microvolt = <0x1dc130>;
							regulator-boot-on;
							regulator-always-on;
							phandle = <0x3a>;
						};

						BUCK6 {
							regulator-name = "BUCK6";
							regulator-min-microvolt = <0xff208>;
							regulator-max-microvolt = <0x119fb8>;
							regulator-boot-on;
							regulator-always-on;
						};

						LDO1 {
							regulator-name = "LDO1";
							regulator-min-microvolt = <0x192d50>;
							regulator-max-microvolt = <0x1dc130>;
							regulator-boot-on;
							regulator-always-on;
						};

						LDO3 {
							regulator-name = "LDO3";
							regulator-min-microvolt = <0x1a17b0>;
							regulator-max-microvolt = <0x1cd6d0>;
							regulator-boot-on;
							regulator-always-on;
						};

						LDO5 {
							regulator-name = "LDO5";
							regulator-min-microvolt = <0x1b7740>;
							regulator-max-microvolt = <0x325aa0>;
							regulator-boot-on;
							regulator-always-on;
						};
					};
				};
			};

			i2c@30a30000 {
				compatible = "fsl,imx8mp-i2c", "fsl,imx21-i2c";
				#address-cells = <0x01>;
				#size-cells = <0x00>;
				reg = <0x30a30000 0x10000>;
				interrupts = <0x00 0x24 0x04>;
				clocks = <0x02 0xce>;
				status = "okay";
				clock-frequency = <0x61a80>;
				pinctrl-names = "default";
				pinctrl-0 = <0x39>;
				phandle = <0xce>;

				hdmi@3d {
					compatible = "adi,adv7535";
					reg = <0x3d>;
					interrupt-parent = <0x38>;
					interrupts = <0x09 0x02>;
					adi,dsi-lanes = <0x04>;
					avdd-supply = <0x3a>;
					dvdd-supply = <0x3a>;
					pvdd-supply = <0x3a>;
					a2vdd-supply = <0x3a>;
					v3p3-supply = <0x3b>;
					v1p2-supply = <0x3a>;

					ports {
						#address-cells = <0x01>;
						#size-cells = <0x00>;

						port@0 {
							reg = <0x00>;

							endpoint {
								remote-endpoint = <0x3c>;
								phandle = <0x62>;
							};
						};

						port@1 {
							reg = <0x01>;

							endpoint {
								remote-endpoint = <0x3d>;
								phandle = <0x8c>;
							};
						};
					};
				};
			};

			i2c@30a40000 {
				compatible = "fsl,imx8mp-i2c", "fsl,imx21-i2c";
				#address-cells = <0x01>;
				#size-cells = <0x00>;
				reg = <0x30a40000 0x10000>;
				interrupts = <0x00 0x25 0x04>;
				clocks = <0x02 0xcf>;
				status = "okay";
				clock-frequency = <0x61a80>;
				pinctrl-names = "default";
				pinctrl-0 = <0x3e>;
				phandle = <0xcf>;

				codec@1a {
					compatible = "wlf,wm8960";
					reg = <0x1a>;
					#sound-dai-cells = <0x00>;
					clocks = <0x3f 0x09>;
					clock-names = "mclk";
					wlf,shared-lrclk;
					wlf,hp-cfg = <0x03 0x02 0x03>;
					wlf,gpio-cfg = <0x01 0x03>;
					SPKVDD1-supply = <0x40>;
					phandle = <0x98>;
				};

				gpio@20 {
					compatible = "ti,tca6416";
					reg = <0x20>;
					gpio-controller;
					#gpio-cells = <0x02>;
					interrupt-controller;
					#interrupt-cells = <0x02>;
					pinctrl-names = "default";
					pinctrl-0 = <0x41>;
					interrupt-parent = <0x38>;
					interrupts = <0x0c 0x08>;
					gpio-line-names = "EXT_PWREN1", "EXT_PWREN2", "CAN1/I2C5_SEL", "PDM/CAN2_SEL", "FAN_EN", "PWR_MEAS_IO1", "PWR_MEAS_IO2", "EXP_P0_7", "EXP_P1_0", "EXP_P1_1", "EXP_P1_2", "EXP_P1_3", "EXP_P1_4", "EXP_P1_5", "EXP_P1_6", "EXP_P1_7";
					phandle = <0x94>;
				};
			};

			i2c@30a50000 {
				compatible = "fsl,imx8mp-i2c", "fsl,imx21-i2c";
				#address-cells = <0x01>;
				#size-cells = <0x00>;
				reg = <0x30a50000 0x10000>;
				interrupts = <0x00 0x26 0x04>;
				clocks = <0x02 0xd0>;
				status = "disabled";
				phandle = <0xd0>;
			};

			serial@30a60000 {
				compatible = "fsl,imx8mp-uart", "fsl,imx6q-uart";
				reg = <0x30a60000 0x10000>;
				interrupts = <0x00 0x1d 0x04>;
				clocks = <0x02 0xfe 0x02 0xfe>;
				clock-names = "ipg", "per";
				dmas = <0x2d 0x1c 0x04 0x00 0x2d 0x1d 0x04 0x00>;
				dma-names = "rx", "tx";
				status = "disabled";
				phandle = <0xd1>;
			};

			mailbox@30aa0000 {
				compatible = "fsl,imx8mp-mu", "fsl,imx6sx-mu";
				reg = <0x30aa0000 0x10000>;
				interrupts = <0x00 0x58 0x04>;
				clocks = <0x02 0xd5>;
				#mbox-cells = <0x02>;
				phandle = <0xd2>;
			};

			mailbox@30e60000 {
				compatible = "fsl,imx8mp-mu", "fsl,imx6sx-mu";
				reg = <0x30e60000 0x10000>;
				interrupts = <0x00 0x88 0x04>;
				#mbox-cells = <0x02>;
				status = "disabled";
				phandle = <0x88>;
			};

			i2c@30ad0000 {
				compatible = "fsl,imx8mp-i2c", "fsl,imx21-i2c";
				#address-cells = <0x01>;
				#size-cells = <0x00>;
				reg = <0x30ad0000 0x10000>;
				interrupts = <0x00 0x4c 0x04>;
				clocks = <0x02 0xe7>;
				status = "disabled";
				clock-frequency = <0x186a0>;
				pinctrl-names = "default";
				pinctrl-0 = <0x42>;
				phandle = <0xd3>;
			};

			i2c@30ae0000 {
				compatible = "fsl,imx8mp-i2c", "fsl,imx21-i2c";
				#address-cells = <0x01>;
				#size-cells = <0x00>;
				reg = <0x30ae0000 0x10000>;
				interrupts = <0x00 0x4d 0x04>;
				clocks = <0x02 0xe8>;
				status = "disabled";
				phandle = <0xd4>;
			};

			mmc@30b40000 {
				compatible = "fsl,imx8mp-usdhc", "fsl,imx8mm-usdhc", "fsl,imx7d-usdhc";
				reg = <0x30b40000 0x10000>;
				interrupts = <0x00 0x16 0x04>;
				clocks = <0x02 0x00 0x02 0x5f 0x02 0x101>;
				clock-names = "ipg", "ahb", "per";
				fsl,tuning-start-tap = <0x14>;
				fsl,tuning-step = <0x02>;
				bus-width = <0x04>;
				status = "disabled";
				phandle = <0xd5>;
			};

			mmc@30b50000 {
				compatible = "fsl,imx8mp-usdhc", "fsl,imx8mm-usdhc", "fsl,imx7d-usdhc";
				reg = <0x30b50000 0x10000>;
				interrupts = <0x00 0x17 0x04>;
				clocks = <0x02 0x00 0x02 0x5f 0x02 0x102>;
				clock-names = "ipg", "ahb", "per";
				fsl,tuning-start-tap = <0x14>;
				fsl,tuning-step = <0x02>;
				bus-width = <0x04>;
				status = "okay";
				assigned-clocks = <0x02 0x89>;
				assigned-clock-rates = <0x17d78400>;
				pinctrl-names = "default", "state_100mhz", "state_200mhz";
				pinctrl-0 = <0x43 0x44>;
				pinctrl-1 = <0x45 0x44>;
				pinctrl-2 = <0x46 0x44>;
				cd-gpios = <0x47 0x0c 0x01>;
				vmmc-supply = <0x48>;
				phandle = <0xd6>;
			};

			mmc@30b60000 {
				compatible = "fsl,imx8mp-usdhc", "fsl,imx8mm-usdhc", "fsl,imx7d-usdhc";
				reg = <0x30b60000 0x10000>;
				interrupts = <0x00 0x18 0x04>;
				clocks = <0x02 0x00 0x02 0x5f 0x02 0x115>;
				clock-names = "ipg", "ahb", "per";
				fsl,tuning-start-tap = <0x14>;
				fsl,tuning-step = <0x02>;
				bus-width = <0x08>;
				status = "okay";
				assigned-clocks = <0x02 0xa9>;
				assigned-clock-rates = <0x17d78400>;
				pinctrl-names = "default", "state_100mhz", "state_200mhz";
				pinctrl-0 = <0x49>;
				pinctrl-1 = <0x4a>;
				pinctrl-2 = <0x4b>;
				non-removable;
				phandle = <0xd7>;
			};

			spi@30bb0000 {
				compatible = "nxp,imx8mp-fspi";
				reg = <0x30bb0000 0x10000 0x8000000 0x10000000>;
				reg-names = "fspi_base", "fspi_mmap";
				interrupts = <0x00 0x6b 0x04>;
				clocks = <0x02 0xe2 0x02 0xe2>;
				clock-names = "fspi_en", "fspi";
				assigned-clock-rates = <0x4c4b400>;
				assigned-clocks = <0x02 0x87>;
				#address-cells = <0x01>;
				#size-cells = <0x00>;
				status = "okay";
				pinctrl-names = "default";
				pinctrl-0 = <0x4c>;
				phandle = <0xd8>;

				flash@0 {
					compatible = "jedec,spi-nor";
					reg = <0x00>;
					spi-max-frequency = <0x4c4b400>;
					spi-tx-bus-width = <0x01>;
					spi-rx-bus-width = <0x04>;
				};
			};

			dma-controller@30bd0000 {
				compatible = "fsl,imx8mp-sdma", "fsl,imx8mq-sdma";
				reg = <0x30bd0000 0x10000>;
				interrupts = <0x00 0x02 0x04>;
				clocks = <0x02 0xec 0x02 0x6b>;
				clock-names = "ipg", "ahb";
				#dma-cells = <0x03>;
				fsl,sdma-ram-script-name = "imx/sdma/sdma-imx7d.bin";
				phandle = <0x2d>;
			};

			ethernet@30be0000 {
				compatible = "fsl,imx8mp-fec", "fsl,imx8mq-fec", "fsl,imx6sx-fec";
				reg = <0x30be0000 0x10000>;
				interrupts = <0x00 0x76 0x04 0x00 0x77 0x04 0x00 0x78 0x04 0x00 0x79 0x04>;
				clocks = <0x02 0xc0 0x02 0xf2 0x02 0x84 0x02 0x83 0x02 0x85>;
				clock-names = "ipg", "ahb", "ptp", "enet_clk_ref", "enet_out";
				assigned-clocks = <0x02 0x5e 0x02 0x84 0x02 0x83 0x02 0x85>;
				assigned-clock-parents = <0x02 0x36 0x02 0x3a 0x02 0x3b 0x02 0x39>;
				assigned-clock-rates = <0x00 0x5f5e100 0x7735940 0x00>;
				fsl,num-tx-queues = <0x03>;
				fsl,num-rx-queues = <0x03>;
				nvmem-cells = <0x4d>;
				nvmem-cell-names = "mac-address";
				fsl,stop-mode = <0x31 0x10 0x03>;
				status = "okay";
				pinctrl-names = "default";
				pinctrl-0 = <0x4e>;
				phy-mode = "rgmii-id";
				phy-handle = <0x4f>;
				fsl,magic-packet;
				phandle = <0xd9>;

				mdio {
					#address-cells = <0x01>;
					#size-cells = <0x00>;

					ethernet-phy@1 {
						compatible = "ethernet-phy-ieee802.3-c22";
						reg = <0x01>;
						eee-broken-1000t;
						reset-gpios = <0x50 0x02 0x01>;
						reset-assert-us = <0x2710>;
						reset-deassert-us = <0x13880>;
						realtek,clkout-disable;
						phandle = <0x4f>;
					};
				};
			};

			ethernet@30bf0000 {
				compatible = "nxp,imx8mp-dwmac-eqos", "snps,dwmac-5.10a";
				reg = <0x30bf0000 0x10000>;
				interrupts = <0x00 0x87 0x04 0x00 0x86 0x04>;
				interrupt-names = "macirq", "eth_wake_irq";
				clocks = <0x02 0xed 0x02 0xe1 0x02 0x82 0x02 0x81>;
				clock-names = "stmmaceth", "pclk", "ptp_ref", "tx";
				assigned-clocks = <0x02 0x5e 0x02 0x82 0x02 0x81>;
				assigned-clock-parents = <0x02 0x36 0x02 0x3a 0x02 0x3b>;
				assigned-clock-rates = <0x00 0x5f5e100 0x7735940>;
				nvmem-cells = <0x51>;
				nvmem-cell-names = "mac-address";
				intf_mode = <0x31 0x04>;
				status = "okay";
				pinctrl-names = "default";
				pinctrl-0 = <0x52>;
				phy-mode = "rgmii-id";
				phy-handle = <0x53>;
				snps,force_thresh_dma_mode;
				snps,mtl-tx-config = <0x54>;
				snps,mtl-rx-config = <0x55>;
				phandle = <0xda>;

				mdio {
					compatible = "snps,dwmac-mdio";
					#address-cells = <0x01>;
					#size-cells = <0x00>;

					ethernet-phy@1 {
						compatible = "ethernet-phy-ieee802.3-c22";
						reg = <0x01>;
						eee-broken-1000t;
						reset-gpios = <0x50 0x16 0x01>;
						reset-assert-us = <0x2710>;
						reset-deassert-us = <0x13880>;
						realtek,clkout-disable;
						phandle = <0x53>;
					};
				};

				tx-queues-config {
					snps,tx-queues-to-use = <0x05>;
					phandle = <0x54>;

					queue0 {
						snps,dcb-algorithm;
						snps,priority = <0x01>;
					};

					queue1 {
						snps,dcb-algorithm;
						snps,priority = <0x02>;
					};

					queue2 {
						snps,dcb-algorithm;
						snps,priority = <0x04>;
					};

					queue3 {
						snps,dcb-algorithm;
						snps,priority = <0x08>;
					};

					queue4 {
						snps,dcb-algorithm;
						snps,priority = <0xf0>;
					};
				};

				rx-queues-config {
					snps,rx-queues-to-use = <0x05>;
					snps,rx-sched-sp;
					phandle = <0x55>;

					queue0 {
						snps,dcb-algorithm;
						snps,priority = <0x01>;
						snps,map-to-dma-channel = <0x00>;
					};

					queue1 {
						snps,dcb-algorithm;
						snps,priority = <0x02>;
						snps,map-to-dma-channel = <0x01>;
					};

					queue2 {
						snps,dcb-algorithm;
						snps,priority = <0x04>;
						snps,map-to-dma-channel = <0x02>;
					};

					queue3 {
						snps,dcb-algorithm;
						snps,priority = <0x08>;
						snps,map-to-dma-channel = <0x03>;
					};

					queue4 {
						snps,dcb-algorithm;
						snps,priority = <0xf0>;
						snps,map-to-dma-channel = <0x04>;
					};
				};
			};
		};

		bus@30c00000 {
			compatible = "fsl,aips-bus", "simple-bus";
			reg = <0x30c00000 0x400000>;
			#address-cells = <0x01>;
			#size-cells = <0x01>;
			ranges;
			phandle = <0xdb>;

			spba-bus@30c00000 {
				compatible = "fsl,spba-bus", "simple-bus";
				reg = <0x30c00000 0x100000>;
				#address-cells = <0x01>;
				#size-cells = <0x01>;
				ranges;

				sai@30c10000 {
					compatible = "fsl,imx8mp-sai", "fsl,imx8mq-sai";
					reg = <0x30c10000 0x10000>;
					#sound-dai-cells = <0x00>;
					clocks = <0x3f 0x00 0x02 0x00 0x3f 0x01 0x3f 0x02 0x3f 0x03>;
					clock-names = "bus", "mclk0", "mclk1", "mclk2", "mclk3";
					dmas = <0x56 0x00 0x02 0x00 0x56 0x01 0x02 0x00>;
					dma-names = "rx", "tx";
					interrupts = <0x00 0x5f 0x04>;
					status = "disabled";
					phandle = <0xdc>;
				};

				sai@30c20000 {
					compatible = "fsl,imx8mp-sai", "fsl,imx8mq-sai";
					reg = <0x30c20000 0x10000>;
					#sound-dai-cells = <0x00>;
					clocks = <0x3f 0x04 0x02 0x00 0x3f 0x05 0x3f 0x06 0x3f 0x07>;
					clock-names = "bus", "mclk0", "mclk1", "mclk2", "mclk3";
					dmas = <0x56 0x02 0x02 0x00 0x56 0x03 0x02 0x00>;
					dma-names = "rx", "tx";
					interrupts = <0x00 0x60 0x04>;
					status = "okay";
					pinctrl-names = "default";
					pinctrl-0 = <0x57>;
					assigned-clocks = <0x02 0x7c>;
					assigned-clock-parents = <0x02 0x26>;
					assigned-clock-rates = <0xbb8000>;
					fsl,sai-mclk-direction-output;
					phandle = <0x9a>;
				};

				sai@30c30000 {
					compatible = "fsl,imx8mp-sai", "fsl,imx8mq-sai";
					reg = <0x30c30000 0x10000>;
					#sound-dai-cells = <0x00>;
					clocks = <0x3f 0x08 0x02 0x00 0x3f 0x09 0x3f 0x0a 0x3f 0x0b>;
					clock-names = "bus", "mclk0", "mclk1", "mclk2", "mclk3";
					dmas = <0x56 0x04 0x02 0x00 0x56 0x05 0x02 0x00>;
					dma-names = "rx", "tx";
					interrupts = <0x00 0x32 0x04>;
					status = "okay";
					pinctrl-names = "default";
					pinctrl-0 = <0x58>;
					assigned-clocks = <0x02 0x7d>;
					assigned-clock-parents = <0x02 0x26>;
					assigned-clock-rates = <0xbb8000>;
					fsl,sai-mclk-direction-output;
					phandle = <0x97>;
				};

				sai@30c50000 {
					compatible = "fsl,imx8mp-sai", "fsl,imx8mq-sai";
					reg = <0x30c50000 0x10000>;
					#sound-dai-cells = <0x00>;
					clocks = <0x3f 0x0c 0x02 0x00 0x3f 0x0d 0x3f 0x0e 0x3f 0x0f>;
					clock-names = "bus", "mclk0", "mclk1", "mclk2", "mclk3";
					dmas = <0x56 0x08 0x02 0x00 0x56 0x09 0x02 0x00>;
					dma-names = "rx", "tx";
					interrupts = <0x00 0x5a 0x04>;
					status = "disabled";
					phandle = <0xdd>;
				};

				sai@30c60000 {
					compatible = "fsl,imx8mp-sai", "fsl,imx8mq-sai";
					reg = <0x30c60000 0x10000>;
					#sound-dai-cells = <0x00>;
					clocks = <0x3f 0x10 0x02 0x00 0x3f 0x11 0x3f 0x12 0x3f 0x13>;
					clock-names = "bus", "mclk0", "mclk1", "mclk2", "mclk3";
					dmas = <0x56 0x0a 0x02 0x00 0x56 0x0b 0x02 0x00>;
					dma-names = "rx", "tx";
					interrupts = <0x00 0x5a 0x04>;
					status = "disabled";
					phandle = <0xde>;
				};

				sai@30c80000 {
					compatible = "fsl,imx8mp-sai", "fsl,imx8mq-sai";
					reg = <0x30c80000 0x10000>;
					#sound-dai-cells = <0x00>;
					clocks = <0x3f 0x14 0x02 0x00 0x3f 0x15 0x3f 0x16 0x3f 0x17>;
					clock-names = "bus", "mclk0", "mclk1", "mclk2", "mclk3";
					dmas = <0x56 0x0c 0x02 0x00 0x56 0x0d 0x02 0x00>;
					dma-names = "rx", "tx";
					interrupts = <0x00 0x6f 0x04>;
					status = "disabled";
					phandle = <0xdf>;
				};

				easrc@30c90000 {
					compatible = "fsl,imx8mp-easrc", "fsl,imx8mn-easrc";
					reg = <0x30c90000 0x10000>;
					interrupts = <0x00 0x7a 0x04>;
					clocks = <0x3f 0x18>;
					clock-names = "mem";
					dmas = <0x56 0x10 0x17 0x00 0x56 0x11 0x17 0x00 0x56 0x12 0x17 0x00 0x56 0x13 0x17 0x00 0x56 0x14 0x17 0x00 0x56 0x15 0x17 0x00 0x56 0x16 0x17 0x00 0x56 0x17 0x17 0x00>;
					dma-names = "ctx0_rx", "ctx0_tx", "ctx1_rx", "ctx1_tx", "ctx2_rx", "ctx2_tx", "ctx3_rx", "ctx3_tx";
					firmware-name = "imx/easrc/easrc-imx8mn.bin";
					fsl,asrc-rate = <0x1f40>;
					fsl,asrc-format = <0x02>;
					status = "disabled";
					phandle = <0xe0>;
				};

				audio-controller@30ca0000 {
					compatible = "fsl,imx8mp-micfil";
					reg = <0x30ca0000 0x10000>;
					#sound-dai-cells = <0x00>;
					interrupts = <0x00 0x6d 0x04 0x00 0x6e 0x04 0x00 0x2c 0x04 0x00 0x2d 0x04>;
					clocks = <0x3f 0x19 0x3f 0x36 0x02 0x26 0x02 0x27 0x02 0x06>;
					clock-names = "ipg_clk", "ipg_clk_app", "pll8k", "pll11k", "clkext3";
					dmas = <0x56 0x18 0x19 0x80000000>;
					dma-names = "rx";
					status = "okay";
					pinctrl-names = "default";
					pinctrl-0 = <0x59>;
					assigned-clocks = <0x02 0xb4>;
					assigned-clock-parents = <0x02 0x26>;
					assigned-clock-rates = <0xbb80000>;
					phandle = <0x9d>;
				};

				aud2htx@30cb0000 {
					compatible = "fsl,imx8mp-aud2htx";
					reg = <0x30cb0000 0x10000>;
					interrupts = <0x00 0x82 0x04>;
					clocks = <0x3f 0x21>;
					clock-names = "bus";
					dmas = <0x56 0x1a 0x02 0x00>;
					dma-names = "tx";
					status = "okay";
					phandle = <0x9c>;
				};

				xcvr@30cc0000 {
					compatible = "fsl,imx8mp-xcvr";
					reg = <0x30cc0000 0x800 0x30cc0800 0x400 0x30cc0c00 0x80 0x30cc0e00 0x80>;
					reg-names = "ram", "regs", "rxfifo", "txfifo";
					interrupts = <0x00 0x80 0x04 0x00 0x81 0x04 0x00 0x92 0x04>;
					clocks = <0x3f 0x1f 0x3f 0x26 0x3f 0x1c 0x3f 0x23>;
					clock-names = "ipg", "phy", "spba", "pll_ipg";
					dmas = <0x56 0x1e 0x02 0x00 0x56 0x1f 0x02 0x00>;
					dma-names = "rx", "tx";
					resets = <0x3f 0x00>;
					status = "okay";
					#sound-dai-cells = <0x00>;
					phandle = <0x9e>;
				};
			};

			dma-controller@30e00000 {
				compatible = "fsl,imx8mp-sdma", "fsl,imx8mq-sdma";
				reg = <0x30e00000 0x10000>;
				#dma-cells = <0x03>;
				clocks = <0x3f 0x1b 0x02 0x11c>;
				clock-names = "ipg", "ahb";
				interrupts = <0x00 0x22 0x04>;
				fsl,sdma-ram-script-name = "imx/sdma/sdma-imx7d.bin";
				phandle = <0xe1>;
			};

			dma-controller@30e10000 {
				compatible = "fsl,imx8mp-sdma", "fsl,imx8mq-sdma";
				reg = <0x30e10000 0x10000>;
				#dma-cells = <0x03>;
				clocks = <0x3f 0x1a 0x02 0x11c>;
				clock-names = "ipg", "ahb";
				interrupts = <0x00 0x67 0x04>;
				fsl,sdma-ram-script-name = "imx/sdma/sdma-imx7d.bin";
				phandle = <0x56>;
			};

			clock-controller@30e20000 {
				compatible = "fsl,imx8mp-audio-blk-ctrl";
				reg = <0x30e20000 0x10000>;
				#clock-cells = <0x01>;
				#reset-cells = <0x01>;
				clocks = <0x02 0x11c 0x02 0x7b 0x02 0x7c 0x02 0x7d 0x02 0x7f 0x02 0x80 0x02 0xb6>;
				clock-names = "ahb", "sai1", "sai2", "sai3", "sai5", "sai6", "sai7";
				power-domains = <0x5a>;
				assigned-clocks = <0x02 0x12 0x02 0x13>;
				assigned-clock-rates = <0x17700000 0x15888000>;
				phandle = <0x3f>;
			};
		};

		interconnect@32700000 {
			compatible = "fsl,imx8mp-noc", "fsl,imx8m-noc";
			reg = <0x32700000 0x100000>;
			clocks = <0x02 0x67>;
			#interconnect-cells = <0x01>;
			operating-points-v2 = <0x5b>;
			phandle = <0x69>;

			opp-table {
				compatible = "operating-points-v2";
				phandle = <0x5b>;

				opp-200000000 {
					opp-hz = <0x00 0xbebc200>;
				};

				opp-1000000000 {
					opp-hz = <0x00 0x3b9aca00>;
				};
			};
		};

		bus@32c00000 {
			compatible = "fsl,aips-bus", "simple-bus";
			reg = <0x32c00000 0x400000>;
			#address-cells = <0x01>;
			#size-cells = <0x01>;
			ranges;
			phandle = <0xe2>;

			isi@32e00000 {
				compatible = "fsl,imx8mp-isi";
				reg = <0x32e00000 0x4000>;
				interrupts = <0x00 0x10 0x04 0x00 0x2a 0x04>;
				clocks = <0x02 0x10e 0x02 0x10d>;
				clock-names = "axi", "apb";
				fsl,blk-ctrl = <0x5c>;
				power-domains = <0x5c 0x03>;
				status = "disabled";
				phandle = <0xe3>;

				ports {
					#address-cells = <0x01>;
					#size-cells = <0x00>;

					port@0 {
						reg = <0x00>;

						endpoint {
							remote-endpoint = <0x5d>;
							phandle = <0x5f>;
						};
					};

					port@1 {
						reg = <0x01>;

						endpoint {
							remote-endpoint = <0x5e>;
							phandle = <0x60>;
						};
					};
				};
			};

			dwe@32e30000 {
				compatible = "nxp,imx8mp-dw100";
				reg = <0x32e30000 0x10000>;
				interrupts = <0x00 0x64 0x04>;
				clocks = <0x02 0x10e 0x02 0x10d>;
				clock-names = "axi", "ahb";
				power-domains = <0x5c 0x07>;
				phandle = <0xe4>;
			};

			csi@32e40000 {
				compatible = "fsl,imx8mp-mipi-csi2", "fsl,imx8mm-mipi-csi2";
				reg = <0x32e40000 0x10000>;
				interrupts = <0x00 0x11 0x04>;
				clock-frequency = <0xfdad680>;
				clocks = <0x02 0x10d 0x02 0x10f 0x02 0x113 0x02 0x10e>;
				clock-names = "pclk", "wrap", "phy", "axi";
				assigned-clocks = <0x02 0xaa 0x02 0xab>;
				assigned-clock-parents = <0x02 0x41 0x02 0x02>;
				assigned-clock-rates = <0xfdad680>;
				power-domains = <0x5c 0x01>;
				status = "disabled";
				phandle = <0xe5>;

				ports {
					#address-cells = <0x01>;
					#size-cells = <0x00>;

					port@0 {
						reg = <0x00>;
					};

					port@1 {
						reg = <0x01>;

						endpoint {
							remote-endpoint = <0x5f>;
							phandle = <0x5d>;
						};
					};
				};
			};

			csi@32e50000 {
				compatible = "fsl,imx8mp-mipi-csi2", "fsl,imx8mm-mipi-csi2";
				reg = <0x32e50000 0x10000>;
				interrupts = <0x00 0x50 0x04>;
				clock-frequency = <0xfdad680>;
				clocks = <0x02 0x10d 0x02 0x110 0x02 0x113 0x02 0x10e>;
				clock-names = "pclk", "wrap", "phy", "axi";
				assigned-clocks = <0x02 0xad 0x02 0xab>;
				assigned-clock-parents = <0x02 0x41 0x02 0x02>;
				assigned-clock-rates = <0xfdad680>;
				power-domains = <0x5c 0x04>;
				status = "disabled";
				phandle = <0xe6>;

				ports {
					#address-cells = <0x01>;
					#size-cells = <0x00>;

					port@0 {
						reg = <0x00>;
					};

					port@1 {
						reg = <0x01>;

						endpoint {
							remote-endpoint = <0x60>;
							phandle = <0x5e>;
						};
					};
				};
			};

			dsi@32e60000 {
				compatible = "fsl,imx8mp-mipi-dsim";
				reg = <0x32e60000 0x400>;
				clocks = <0x02 0x10d 0x02 0xab>;
				clock-names = "bus_clk", "sclk_mipi";
				assigned-clocks = <0x02 0x62 0x02 0xab>;
				assigned-clock-parents = <0x02 0x38 0x02 0x02>;
				assigned-clock-rates = <0xbebc200 0x16e3600>;
				samsung,pll-clock-frequency = <0x16e3600>;
				interrupts = <0x00 0x12 0x04>;
				power-domains = <0x5c 0x00>;
				status = "okay";
				samsung,esc-clock-frequency = <0x989680>;
				phandle = <0xe7>;

				ports {
					#address-cells = <0x01>;
					#size-cells = <0x00>;

					port@0 {
						reg = <0x00>;

						endpoint {
							remote-endpoint = <0x61>;
							phandle = <0x63>;
						};
					};

					port@1 {
						reg = <0x01>;

						endpoint {
							remote-endpoint = <0x62>;
							data-lanes = <0x01 0x02 0x03 0x04>;
							phandle = <0x3c>;
						};
					};
				};
			};

			display-controller@32e80000 {
				compatible = "fsl,imx8mp-lcdif";
				reg = <0x32e80000 0x10000>;
				clocks = <0x02 0x111 0x02 0x10d 0x02 0x10e>;
				clock-names = "pix", "axi", "disp_axi";
				interrupts = <0x00 0x05 0x04>;
				power-domains = <0x5c 0x02>;
				status = "okay";
				phandle = <0xe8>;

				port {

					endpoint {
						remote-endpoint = <0x63>;
						phandle = <0x61>;
					};
				};
			};

			display-controller@32e90000 {
				compatible = "fsl,imx8mp-lcdif";
				reg = <0x32e90000 0x10000>;
				interrupts = <0x00 0x06 0x04>;
				clocks = <0x02 0x112 0x02 0x10d 0x02 0x10e>;
				clock-names = "pix", "axi", "disp_axi";
				power-domains = <0x5c 0x05>;
				status = "disabled";
				phandle = <0xe9>;

				port {

					endpoint {
						remote-endpoint = <0x64>;
						phandle = <0x6a>;
					};
				};
			};

			blk-ctrl@32ec0000 {
				compatible = "fsl,imx8mp-media-blk-ctrl", "syscon";
				reg = <0x32ec0000 0x10000>;
				#address-cells = <0x01>;
				#size-cells = <0x01>;
				power-domains = <0x65 0x66 0x66 0x65 0x65 0x67 0x65 0x68 0x68 0x67>;
				power-domain-names = "bus", "mipi-dsi1", "mipi-csi1", "lcdif1", "isi", "mipi-csi2", "lcdif2", "isp", "dwe", "mipi-dsi2";
				interconnects = <0x69 0x1c 0x69 0x1b 0x69 0x1d 0x69 0x1b 0x69 0x1e 0x69 0x1b 0x69 0x1f 0x69 0x1b 0x69 0x20 0x69 0x1b 0x69 0x21 0x69 0x1b 0x69 0x22 0x69 0x1b 0x69 0x23 0x69 0x1b>;
				interconnect-names = "lcdif-rd", "lcdif-wr", "isi0", "isi1", "isi2", "isp0", "isp1", "dwe";
				clocks = <0x02 0x10d 0x02 0x10e 0x02 0x10f 0x02 0x110 0x02 0x111 0x02 0x112 0x02 0x114 0x02 0x113>;
				clock-names = "apb", "axi", "cam1", "cam2", "disp1", "disp2", "isp", "phy";
				assigned-clocks = <0x02 0x61 0x02 0x62 0x02 0xac 0x02 0x139 0x02 0x14>;
				assigned-clock-parents = <0x02 0x41 0x02 0x38 0x02 0x28 0x02 0x28>;
				assigned-clock-rates = <0x1dcd6500 0xbebc200 0x00 0x00 0x3df582e0>;
				#power-domain-cells = <0x01>;
				phandle = <0x5c>;

				bridge@5c {
					compatible = "fsl,imx8mp-ldb";
					reg = <0x5c 0x04 0x128 0x04>;
					reg-names = "ldb", "lvds";
					clocks = <0x02 0x149>;
					clock-names = "ldb";
					assigned-clocks = <0x02 0xae>;
					assigned-clock-parents = <0x02 0x28>;
					status = "disabled";
					phandle = <0xea>;

					ports {
						#address-cells = <0x01>;
						#size-cells = <0x00>;

						port@0 {
							reg = <0x00>;

							endpoint {
								remote-endpoint = <0x6a>;
								phandle = <0x64>;
							};
						};

						port@1 {
							reg = <0x01>;

							endpoint {
								phandle = <0xeb>;
							};
						};

						port@2 {
							reg = <0x02>;

							endpoint {
								phandle = <0xec>;
							};
						};
					};
				};
			};

			pcie-phy@32f00000 {
				compatible = "fsl,imx8mp-pcie-phy";
				reg = <0x32f00000 0x10000>;
				resets = <0x6b 0x18 0x6b 0x19>;
				reset-names = "pciephy", "perst";
				power-domains = <0x6c 0x04>;
				#phy-cells = <0x00>;
				status = "okay";
				fsl,refclk-pad-mode = <0x01>;
				clocks = <0x6d>;
				clock-names = "ref";
				phandle = <0x7b>;
			};

			blk-ctrl@32f10000 {
				compatible = "fsl,imx8mp-hsio-blk-ctrl", "syscon";
				reg = <0x32f10000 0x24>;
				clocks = <0x02 0xff 0x02 0xd9>;
				clock-names = "usb", "pcie";
				power-domains = <0x6e 0x6e 0x6f 0x70 0x6e 0x71>;
				power-domain-names = "bus", "usb", "usb-phy1", "usb-phy2", "pcie", "pcie-phy";
				interconnects = <0x69 0x17 0x69 0x16 0x69 0x18 0x69 0x16 0x69 0x19 0x69 0x16 0x69 0x1a 0x69 0x16>;
				interconnect-names = "noc-pcie", "usb1", "usb2", "pcie";
				#power-domain-cells = <0x01>;
				#clock-cells = <0x00>;
				phandle = <0x6c>;
			};

			blk-ctrl@32fc0000 {
				compatible = "fsl,imx8mp-hdmi-blk-ctrl", "syscon";
				reg = <0x32fc0000 0x1000>;
				clocks = <0x02 0x63 0x02 0x116 0x02 0xa8 0x02 0xa7 0x02 0xa6>;
				clock-names = "apb", "axi", "ref_266m", "ref_24m", "fdcc";
				power-domains = <0x72 0x72 0x72 0x72 0x72 0x72 0x72 0x73 0x72 0x72>;
				power-domain-names = "bus", "irqsteer", "lcdif", "pai", "pvi", "trng", "hdmi-tx", "hdmi-tx-phy", "hdcp", "hrv";
				#power-domain-cells = <0x01>;
				phandle = <0x74>;
			};

			interrupt-controller@32fc2000 {
				compatible = "fsl,imx8mp-irqsteer", "fsl,imx-irqsteer";
				reg = <0x32fc2000 0x1000>;
				interrupts = <0x00 0x2b 0x04>;
				interrupt-controller;
				#interrupt-cells = <0x01>;
				fsl,channel = <0x01>;
				fsl,num-irqs = <0x40>;
				clocks = <0x02 0x63>;
				clock-names = "ipg";
				power-domains = <0x74 0x00>;
				phandle = <0x75>;
			};

			display-bridge@32fc4000 {
				compatible = "fsl,imx8mp-hdmi-pvi";
				reg = <0x32fc4000 0x1000>;
				interrupt-parent = <0x75>;
				interrupts = <0x0c>;
				power-domains = <0x74 0x03>;
				status = "disabled";
				phandle = <0xed>;

				ports {
					#address-cells = <0x01>;
					#size-cells = <0x00>;

					port@0 {
						reg = <0x00>;

						endpoint {
							remote-endpoint = <0x76>;
							phandle = <0x79>;
						};
					};

					port@1 {
						reg = <0x01>;

						endpoint {
							remote-endpoint = <0x77>;
							phandle = <0x7a>;
						};
					};
				};
			};

			display-controller@32fc6000 {
				compatible = "fsl,imx8mp-lcdif";
				reg = <0x32fc6000 0x1000>;
				interrupt-parent = <0x75>;
				interrupts = <0x08>;
				clocks = <0x78 0x02 0x63 0x02 0x116>;
				clock-names = "pix", "axi", "disp_axi";
				power-domains = <0x74 0x01>;
				status = "disabled";
				phandle = <0xee>;

				port {

					endpoint {
						remote-endpoint = <0x79>;
						phandle = <0x76>;
					};
				};
			};

			hdmi@32fd8000 {
				compatible = "fsl,imx8mp-hdmi-tx";
				reg = <0x32fd8000 0x7eff>;
				interrupt-parent = <0x75>;
				interrupts = <0x00>;
				clocks = <0x02 0x63 0x02 0xa8 0x02 0x01 0x78>;
				clock-names = "iahb", "isfr", "cec", "pix";
				assigned-clocks = <0x02 0xa8>;
				assigned-clock-parents = <0x02 0x36>;
				power-domains = <0x74 0x05>;
				reg-io-width = <0x01>;
				status = "disabled";
				phandle = <0xef>;

				ports {
					#address-cells = <0x01>;
					#size-cells = <0x00>;

					port@0 {
						reg = <0x00>;

						endpoint {
							remote-endpoint = <0x7a>;
							phandle = <0x77>;
						};
					};

					port@1 {
						reg = <0x01>;
					};
				};
			};

			phy@32fdff00 {
				compatible = "fsl,imx8mp-hdmi-phy";
				reg = <0x32fdff00 0x100>;
				clocks = <0x02 0x63 0x02 0xa7>;
				clock-names = "apb", "ref";
				assigned-clocks = <0x02 0xa7>;
				assigned-clock-parents = <0x02 0x02>;
				power-domains = <0x74 0x06>;
				#clock-cells = <0x00>;
				#phy-cells = <0x00>;
				status = "disabled";
				phandle = <0x78>;
			};
		};

		pcie@33800000 {
			compatible = "fsl,imx8mp-pcie";
			reg = <0x33800000 0x400000 0x1ff00000 0x80000>;
			reg-names = "dbi", "config";
			clocks = <0x02 0x10c 0x02 0x137 0x02 0xd9>;
			clock-names = "pcie", "pcie_bus", "pcie_aux";
			assigned-clocks = <0x02 0x78>;
			assigned-clock-rates = <0x989680>;
			assigned-clock-parents = <0x02 0x39>;
			#address-cells = <0x03>;
			#size-cells = <0x02>;
			device_type = "pci";
			bus-range = <0x00 0xff>;
			ranges = <0x81000000 0x00 0x00 0x1ff80000 0x00 0x10000 0x82000000 0x00 0x18000000 0x18000000 0x00 0x7f00000>;
			num-lanes = <0x01>;
			num-viewport = <0x04>;
			interrupts = <0x00 0x8c 0x04>;
			interrupt-names = "msi";
			#interrupt-cells = <0x01>;
			interrupt-map-mask = <0x00 0x00 0x00 0x07>;
			interrupt-map = <0x00 0x00 0x00 0x01 0x01 0x00 0x7e 0x04 0x00 0x00 0x00 0x02 0x01 0x00 0x7d 0x04 0x00 0x00 0x00 0x03 0x01 0x00 0x7c 0x04 0x00 0x00 0x00 0x04 0x01 0x00 0x7b 0x04>;
			fsl,max-link-speed = <0x03>;
			linux,pci-domain = <0x00>;
			power-domains = <0x6c 0x03>;
			resets = <0x6b 0x1a 0x6b 0x1b>;
			reset-names = "apps", "turnoff";
			phys = <0x7b>;
			phy-names = "pcie-phy";
			status = "okay";
			pinctrl-names = "default";
			pinctrl-0 = <0x7c>;
			reset-gpio = <0x47 0x07 0x01>;
			vpcie-supply = <0x7d>;
			phandle = <0xf0>;
		};

		pcie-ep@33800000 {
			compatible = "fsl,imx8mp-pcie-ep";
			reg = <0x33800000 0x400000 0x18000000 0x8000000>;
			reg-names = "dbi", "addr_space";
			clocks = <0x02 0x10c 0x02 0x137 0x02 0xd9>;
			clock-names = "pcie", "pcie_bus", "pcie_aux";
			assigned-clocks = <0x02 0x78>;
			assigned-clock-rates = <0x989680>;
			assigned-clock-parents = <0x02 0x39>;
			num-lanes = <0x01>;
			interrupts = <0x00 0x7f 0x04>;
			interrupt-names = "dma";
			fsl,max-link-speed = <0x03>;
			power-domains = <0x6c 0x03>;
			resets = <0x6b 0x1a 0x6b 0x1b>;
			reset-names = "apps", "turnoff";
			phys = <0x7b>;
			phy-names = "pcie-phy";
			num-ib-windows = <0x04>;
			num-ob-windows = <0x04>;
			status = "disabled";
			phandle = <0xf1>;
		};

		gpu@38000000 {
			compatible = "vivante,gc";
			reg = <0x38000000 0x8000>;
			interrupts = <0x00 0x03 0x04>;
			clocks = <0x02 0xf8 0x02 0x134 0x02 0x107 0x02 0x66>;
			clock-names = "core", "shader", "bus", "reg";
			assigned-clocks = <0x02 0x133 0x02 0x134>;
			assigned-clock-parents = <0x02 0x38 0x02 0x38>;
			assigned-clock-rates = <0x2faf0800 0x2faf0800>;
			power-domains = <0x7e>;
			phandle = <0xf2>;
		};

		gpu@38008000 {
			compatible = "vivante,gc";
			reg = <0x38008000 0x8000>;
			interrupts = <0x00 0x19 0x04>;
			clocks = <0x02 0xf7 0x02 0x107 0x02 0x66>;
			clock-names = "core", "bus", "reg";
			assigned-clocks = <0x02 0x135>;
			assigned-clock-parents = <0x02 0x38>;
			assigned-clock-rates = <0x2faf0800>;
			power-domains = <0x7f>;
			phandle = <0xf3>;
		};

		video-codec@38300000 {
			compatible = "nxp,imx8mm-vpu-g1";
			reg = <0x38300000 0x10000>;
			interrupts = <0x00 0x07 0x04>;
			clocks = <0x02 0x106>;
			assigned-clocks = <0x02 0x72>;
			assigned-clock-parents = <0x02 0x2b>;
			assigned-clock-rates = <0x23c34600>;
			power-domains = <0x80 0x00>;
			phandle = <0xf4>;
		};

		video-codec@38310000 {
			compatible = "nxp,imx8mq-vpu-g2";
			reg = <0x38310000 0x10000>;
			interrupts = <0x00 0x08 0x04>;
			clocks = <0x02 0x10a>;
			assigned-clocks = <0x02 0x73>;
			assigned-clock-parents = <0x02 0x41>;
			assigned-clock-rates = <0x1dcd6500>;
			power-domains = <0x80 0x01>;
			phandle = <0xf5>;
		};

		blk-ctrl@38330000 {
			compatible = "fsl,imx8mp-vpu-blk-ctrl", "syscon";
			reg = <0x38330000 0x100>;
			#power-domain-cells = <0x01>;
			power-domains = <0x29 0x81 0x82 0x83>;
			power-domain-names = "bus", "g1", "g2", "vc8000e";
			clocks = <0x02 0x106 0x02 0x10a 0x02 0x109>;
			clock-names = "g1", "g2", "vc8000e";
			assigned-clocks = <0x02 0x60 0x02 0x17>;
			assigned-clock-parents = <0x02 0x2b>;
			assigned-clock-rates = <0x23c34600 0x23c34600>;
			interconnects = <0x69 0x25 0x69 0x24 0x69 0x26 0x69 0x24 0x69 0x27 0x69 0x24>;
			interconnect-names = "g1", "g2", "vc8000e";
			phandle = <0x80>;
		};

		npu@38500000 {
			compatible = "vivante,gc";
			reg = <0x38500000 0x200000>;
			interrupts = <0x00 0x0d 0x04>;
			clocks = <0x02 0x10b 0x02 0x10b 0x02 0x69 0x02 0x6a>;
			clock-names = "core", "shader", "bus", "reg";
			power-domains = <0x84>;
			phandle = <0xf6>;
		};

		interrupt-controller@38800000 {
			compatible = "arm,gic-v3";
			reg = <0x38800000 0x10000 0x38880000 0xc0000>;
			#interrupt-cells = <0x03>;
			interrupt-controller;
			interrupts = <0x01 0x09 0x04>;
			interrupt-parent = <0x01>;
			phandle = <0x01>;
		};

		memory-controller@3d400000 {
			compatible = "snps,ddrc-3.80a";
			reg = <0x3d400000 0x400000>;
			interrupts = <0x00 0x93 0x04>;
			phandle = <0xf7>;
		};

		ddr-pmu@3d800000 {
			compatible = "fsl,imx8mp-ddr-pmu", "fsl,imx8m-ddr-pmu";
			reg = <0x3d800000 0x400000>;
			interrupts = <0x00 0x62 0x04>;
		};

		usb-phy@381f0040 {
			compatible = "fsl,imx8mp-usb-phy";
			reg = <0x381f0040 0x40>;
			clocks = <0x02 0x100>;
			clock-names = "phy";
			assigned-clocks = <0x02 0x93>;
			assigned-clock-parents = <0x02 0x02>;
			power-domains = <0x6c 0x01>;
			#phy-cells = <0x00>;
			status = "disabled";
			phandle = <0x85>;
		};

		usb@32f10100 {
			compatible = "fsl,imx8mp-dwc3";
			reg = <0x32f10100 0x08 0x381f0000 0x20>;
			clocks = <0x02 0x10c 0x02 0x140>;
			clock-names = "hsio", "suspend";
			interrupts = <0x00 0x94 0x04>;
			power-domains = <0x6c 0x00>;
			#address-cells = <0x01>;
			#size-cells = <0x01>;
			dma-ranges = <0x40000000 0x40000000 0xc0000000>;
			ranges;
			status = "disabled";
			phandle = <0xf8>;

			usb@38100000 {
				compatible = "snps,dwc3";
				reg = <0x38100000 0x10000>;
				clocks = <0x02 0xff 0x02 0x92 0x02 0x140>;
				clock-names = "bus_early", "ref", "suspend";
				interrupts = <0x00 0x28 0x04>;
				phys = <0x85 0x85>;
				phy-names = "usb2-phy", "usb3-phy";
				snps,gfladj-refclk-lpm-sel-quirk;
				snps,parkmode-disable-ss-quirk;
				phandle = <0xf9>;
			};
		};

		usb-phy@382f0040 {
			compatible = "fsl,imx8mp-usb-phy";
			reg = <0x382f0040 0x40>;
			clocks = <0x02 0x100>;
			clock-names = "phy";
			assigned-clocks = <0x02 0x93>;
			assigned-clock-parents = <0x02 0x02>;
			power-domains = <0x6c 0x02>;
			#phy-cells = <0x00>;
			status = "okay";
			phandle = <0x86>;
		};

		usb@32f10108 {
			compatible = "fsl,imx8mp-dwc3";
			reg = <0x32f10108 0x08 0x382f0000 0x20>;
			clocks = <0x02 0x10c 0x02 0x140>;
			clock-names = "hsio", "suspend";
			interrupts = <0x00 0x95 0x04>;
			power-domains = <0x6c 0x00>;
			#address-cells = <0x01>;
			#size-cells = <0x01>;
			dma-ranges = <0x40000000 0x40000000 0xc0000000>;
			ranges;
			status = "okay";
			phandle = <0xfa>;

			usb@38200000 {
				compatible = "snps,dwc3";
				reg = <0x38200000 0x10000>;
				clocks = <0x02 0xff 0x02 0x92 0x02 0x140>;
				clock-names = "bus_early", "ref", "suspend";
				interrupts = <0x00 0x29 0x04>;
				phys = <0x86 0x86>;
				phy-names = "usb2-phy", "usb3-phy";
				snps,gfladj-refclk-lpm-sel-quirk;
				snps,parkmode-disable-ss-quirk;
				pinctrl-names = "default";
				pinctrl-0 = <0x87>;
				dr_mode = "host";
				status = "okay";
				phandle = <0xfb>;
			};
		};

		dsp@3b6e8000 {
			compatible = "fsl,imx8mp-dsp";
			reg = <0x3b6e8000 0x88000>;
			mbox-names = "txdb0", "txdb1", "rxdb0", "rxdb1";
			mboxes = <0x88 0x02 0x00 0x88 0x02 0x01 0x88 0x03 0x00 0x88 0x03 0x01>;
			memory-region = <0x89>;
			status = "disabled";
			phandle = <0xfc>;
		};
	};

	chosen {
		stdout-path = "/soc@0/bus@30800000/spba-bus@30800000/serial@30890000";
	};

	backlight-lvds {
		compatible = "pwm-backlight";
		pwms = <0x8a 0x00 0x186a0 0x00>;
		brightness-levels = <0x00 0x64>;
		num-interpolated-steps = <0x64>;
		default-brightness-level = <0x64>;
		power-supply = <0x8b>;
		status = "disabled";
		phandle = <0xfd>;
	};

	hdmi-connector {
		compatible = "hdmi-connector";
		label = "hdmi";
		type = "a";

		port {

			endpoint {
				remote-endpoint = <0x8c>;
				phandle = <0x3d>;
			};
		};
	};

	gpio-leds {
		compatible = "gpio-leds";
		pinctrl-names = "default";
		pinctrl-0 = <0x8d>;

		status {
			label = "yellow:status";
			gpios = <0x8e 0x10 0x00>;
			default-state = "on";
		};
	};

	memory@40000000 {
		device_type = "memory";
		reg = <0x00 0x40000000 0x00 0xc0000000 0x01 0x00 0x00 0xc0000000>;
	};

	pcie0-refclk {
		compatible = "fixed-clock";
		#clock-cells = <0x00>;
		clock-frequency = <0x5f5e100>;
		phandle = <0x6d>;
	};

	regulator-audio-pwr {
		compatible = "regulator-fixed";
		pinctrl-names = "default";
		pinctrl-0 = <0x8f>;
		regulator-name = "audio-pwr";
		regulator-min-microvolt = <0x325aa0>;
		regulator-max-microvolt = <0x325aa0>;
		gpio = <0x50 0x1d 0x00>;
		enable-active-high;
		phandle = <0x40>;
	};

	regulator-can1-stby {
		compatible = "regulator-fixed";
		regulator-name = "can1-stby";
		pinctrl-names = "default";
		pinctrl-0 = <0x90>;
		regulator-min-microvolt = <0x325aa0>;
		regulator-max-microvolt = <0x325aa0>;
		gpio = <0x91 0x05 0x00>;
		enable-active-high;
		phandle = <0x33>;
	};

	regulator-can2-stby {
		compatible = "regulator-fixed";
		regulator-name = "can2-stby";
		pinctrl-names = "default";
		pinctrl-0 = <0x92>;
		regulator-min-microvolt = <0x325aa0>;
		regulator-max-microvolt = <0x325aa0>;
		gpio = <0x50 0x1b 0x00>;
		enable-active-high;
		phandle = <0x35>;
	};

	regulator-pcie {
		compatible = "regulator-fixed";
		pinctrl-names = "default";
		pinctrl-0 = <0x93>;
		regulator-name = "MPCIE_3V3";
		regulator-min-microvolt = <0x325aa0>;
		regulator-max-microvolt = <0x325aa0>;
		gpio = <0x47 0x06 0x00>;
		enable-active-high;
		phandle = <0x7d>;
	};

	regulator-per-12v {
		compatible = "regulator-fixed";
		regulator-name = "PER_12V";
		regulator-min-microvolt = <0xb71b00>;
		regulator-max-microvolt = <0xb71b00>;
		gpio = <0x94 0x01 0x00>;
		enable-active-high;
		phandle = <0x8b>;
	};

	regulator-usdhc2 {
		compatible = "regulator-fixed";
		pinctrl-names = "default";
		pinctrl-0 = <0x95>;
		regulator-name = "VSD_3V3";
		regulator-min-microvolt = <0x325aa0>;
		regulator-max-microvolt = <0x325aa0>;
		gpio = <0x47 0x13 0x00>;
		enable-active-high;
		phandle = <0x48>;
	};

	regulator-vext-3v3 {
		compatible = "regulator-fixed";
		regulator-name = "VEXT_3V3";
		regulator-min-microvolt = <0x325aa0>;
		regulator-max-microvolt = <0x325aa0>;
		phandle = <0x3b>;
	};

	audio-codec-bt-sco {
		compatible = "linux,bt-sco";
		#sound-dai-cells = <0x01>;
		phandle = <0x9b>;
	};

	sound {
		compatible = "simple-audio-card";
		simple-audio-card,name = "wm8960-audio";
		simple-audio-card,format = "i2s";
		simple-audio-card,frame-master = <0x96>;
		simple-audio-card,bitclock-master = <0x96>;
		simple-audio-card,widgets = "Headphone", "Headphone Jack", "Speaker", "External Speaker", "Microphone", "Mic Jack";
		simple-audio-card,routing = "Headphone Jack", "HP_L", "Headphone Jack", "HP_R", "External Speaker", "SPK_LP", "External Speaker", "SPK_LN", "External Speaker", "SPK_RP", "External Speaker", "SPK_RN", "LINPUT1", "Mic Jack", "LINPUT3", "Mic Jack", "Mic Jack", "MICB";

		simple-audio-card,cpu {
			sound-dai = <0x97>;
			phandle = <0x96>;
		};

		simple-audio-card,codec {
			sound-dai = <0x98>;
		};
	};

	sound-bt-sco {
		compatible = "simple-audio-card";
		simple-audio-card,name = "bt-sco-audio";
		simple-audio-card,format = "dsp_a";
		simple-audio-card,bitclock-inversion;
		simple-audio-card,frame-master = <0x99>;
		simple-audio-card,bitclock-master = <0x99>;

		simple-audio-card,cpu {
			sound-dai = <0x9a>;
			dai-tdm-slot-num = <0x02>;
			dai-tdm-slot-width = <0x10>;
			phandle = <0x99>;
		};

		simple-audio-card,codec {
			sound-dai = <0x9b 0x01>;
		};
	};

	sound-hdmi {
		compatible = "fsl,imx-audio-hdmi";
		model = "audio-hdmi";
		audio-cpu = <0x9c>;
		hdmi-out;
	};

	sound-micfil {
		compatible = "fsl,imx-audio-card";
		model = "micfil-audio";

		pri-dai-link {
			link-name = "micfil hifi";
			format = "i2s";

			cpu {
				sound-dai = <0x9d>;
			};
		};
	};

	sound-xcvr {
		compatible = "fsl,imx-audio-card";
		model = "imx-audio-xcvr";

		pri-dai-link {
			link-name = "XCVR PCM";

			cpu {
				sound-dai = <0x9e>;
			};
		};
	};

	__symbols__ {
		A53_0 = "/cpus/cpu@0";
		A53_1 = "/cpus/cpu@1";
		A53_2 = "/cpus/cpu@2";
		A53_3 = "/cpus/cpu@3";
		A53_L2 = "/cpus/l2-cache0";
		a53_opp_table = "/opp-table";
		osc_32k = "/clock-osc-32k";
		osc_24m = "/clock-osc-24m";
		clk_ext1 = "/clock-ext1";
		clk_ext2 = "/clock-ext2";
		clk_ext3 = "/clock-ext3";
		clk_ext4 = "/clock-ext4";
		ca_funnel_in_port0 = "/funnel/in-ports/port@0/endpoint";
		ca_funnel_in_port1 = "/funnel/in-ports/port@1/endpoint";
		ca_funnel_in_port2 = "/funnel/in-ports/port@2/endpoint";
		ca_funnel_in_port3 = "/funnel/in-ports/port@3/endpoint";
		ca_funnel_out_port0 = "/funnel/out-ports/port/endpoint";
		dsp_reserved = "/reserved-memory/dsp@92400000";
		dsp_vdev0vring0 = "/reserved-memory/vdev0vring0@942f0000";
		dsp_vdev0vring1 = "/reserved-memory/vdev0vring1@942f8000";
		dsp_vdev0buffer = "/reserved-memory/vdev0buffer@94300000";
		cpu_alert0 = "/thermal-zones/cpu-thermal/trips/trip0";
		cpu_crit0 = "/thermal-zones/cpu-thermal/trips/trip1";
		soc_alert0 = "/thermal-zones/soc-thermal/trips/trip0";
		soc_crit0 = "/thermal-zones/soc-thermal/trips/trip1";
		soc = "/soc@0";
		etm0 = "/soc@0/etm@28440000";
		etm0_out_port = "/soc@0/etm@28440000/out-ports/port/endpoint";
		etm1 = "/soc@0/etm@28540000";
		etm1_out_port = "/soc@0/etm@28540000/out-ports/port/endpoint";
		etm2 = "/soc@0/etm@28640000";
		etm2_out_port = "/soc@0/etm@28640000/out-ports/port/endpoint";
		etm3 = "/soc@0/etm@28740000";
		etm3_out_port = "/soc@0/etm@28740000/out-ports/port/endpoint";
		hugo_funnel_in_port0 = "/soc@0/funnel@28c03000/in-ports/port@0/endpoint";
		hugo_funnel_in_port1 = "/soc@0/funnel@28c03000/in-ports/port@1/endpoint";
		hugo_funnel_in_port2 = "/soc@0/funnel@28c03000/in-ports/port@2/endpoint";
		hugo_funnel_out_port0 = "/soc@0/funnel@28c03000/out-ports/port/endpoint";
		etf_in_port = "/soc@0/etf@28c04000/in-ports/port/endpoint";
		etf_out_port = "/soc@0/etf@28c04000/out-ports/port/endpoint";
		etr_in_port = "/soc@0/etr@28c06000/in-ports/port/endpoint";
		aips1 = "/soc@0/bus@30000000";
		gpio1 = "/soc@0/bus@30000000/gpio@30200000";
		gpio2 = "/soc@0/bus@30000000/gpio@30210000";
		gpio3 = "/soc@0/bus@30000000/gpio@30220000";
		gpio4 = "/soc@0/bus@30000000/gpio@30230000";
		gpio5 = "/soc@0/bus@30000000/gpio@30240000";
		tmu = "/soc@0/bus@30000000/tmu@30260000";
		wdog1 = "/soc@0/bus@30000000/watchdog@30280000";
		wdog2 = "/soc@0/bus@30000000/watchdog@30290000";
		wdog3 = "/soc@0/bus@30000000/watchdog@302a0000";
		gpt1 = "/soc@0/bus@30000000/timer@302d0000";
		gpt2 = "/soc@0/bus@30000000/timer@302e0000";
		gpt3 = "/soc@0/bus@30000000/timer@302f0000";
		iomuxc = "/soc@0/bus@30000000/pinctrl@30330000";
		pinctrl_audio_pwr_reg = "/soc@0/bus@30000000/pinctrl@30330000/audiopwrreggrp";
		pinctrl_eqos = "/soc@0/bus@30000000/pinctrl@30330000/eqosgrp";
		pinctrl_fec = "/soc@0/bus@30000000/pinctrl@30330000/fecgrp";
		pinctrl_flexcan1 = "/soc@0/bus@30000000/pinctrl@30330000/flexcan1grp";
		pinctrl_flexcan2 = "/soc@0/bus@30000000/pinctrl@30330000/flexcan2grp";
		pinctrl_flexcan1_reg = "/soc@0/bus@30000000/pinctrl@30330000/flexcan1reggrp";
		pinctrl_flexcan2_reg = "/soc@0/bus@30000000/pinctrl@30330000/flexcan2reggrp";
		pinctrl_flexspi0 = "/soc@0/bus@30000000/pinctrl@30330000/flexspi0grp";
		pinctrl_gpio_led = "/soc@0/bus@30000000/pinctrl@30330000/gpioledgrp";
		pinctrl_hog = "/soc@0/bus@30000000/pinctrl@30330000/hoggrp";
		pinctrl_i2c1 = "/soc@0/bus@30000000/pinctrl@30330000/i2c1grp";
		pinctrl_i2c2 = "/soc@0/bus@30000000/pinctrl@30330000/i2c2grp";
		pinctrl_i2c3 = "/soc@0/bus@30000000/pinctrl@30330000/i2c3grp";
		pinctrl_i2c5 = "/soc@0/bus@30000000/pinctrl@30330000/i2c5grp";
		pinctrl_pcie0 = "/soc@0/bus@30000000/pinctrl@30330000/pcie0grp";
		pinctrl_pcie0_reg = "/soc@0/bus@30000000/pinctrl@30330000/pcie0reggrp";
		pinctrl_pdm = "/soc@0/bus@30000000/pinctrl@30330000/pdmgrp";
		pinctrl_pmic = "/soc@0/bus@30000000/pinctrl@30330000/pmicgrp";
		pinctrl_pca6416_int = "/soc@0/bus@30000000/pinctrl@30330000/pca6416_int_grp";
		pinctrl_pwm1 = "/soc@0/bus@30000000/pinctrl@30330000/pwm1grp";
		pinctrl_pwm2 = "/soc@0/bus@30000000/pinctrl@30330000/pwm2grp";
		pinctrl_pwm4 = "/soc@0/bus@30000000/pinctrl@30330000/pwm4grp";
		pinctrl_reg_usdhc2_vmmc = "/soc@0/bus@30000000/pinctrl@30330000/regusdhc2vmmcgrp";
		pinctrl_uart1 = "/soc@0/bus@30000000/pinctrl@30330000/uart1grp";
		pinctrl_sai2 = "/soc@0/bus@30000000/pinctrl@30330000/sai2grp";
		pinctrl_sai3 = "/soc@0/bus@30000000/pinctrl@30330000/sai3grp";
		pinctrl_uart2 = "/soc@0/bus@30000000/pinctrl@30330000/uart2grp";
		pinctrl_usb1_vbus = "/soc@0/bus@30000000/pinctrl@30330000/usb1grp";
		pinctrl_uart3 = "/soc@0/bus@30000000/pinctrl@30330000/uart3grp";
		pinctrl_usdhc2 = "/soc@0/bus@30000000/pinctrl@30330000/usdhc2grp";
		pinctrl_usdhc2_100mhz = "/soc@0/bus@30000000/pinctrl@30330000/usdhc2-100mhzgrp";
		pinctrl_usdhc2_200mhz = "/soc@0/bus@30000000/pinctrl@30330000/usdhc2-200mhzgrp";
		pinctrl_usdhc2_gpio = "/soc@0/bus@30000000/pinctrl@30330000/usdhc2gpiogrp";
		pinctrl_usdhc3 = "/soc@0/bus@30000000/pinctrl@30330000/usdhc3grp";
		pinctrl_usdhc3_100mhz = "/soc@0/bus@30000000/pinctrl@30330000/usdhc3-100mhzgrp";
		pinctrl_usdhc3_200mhz = "/soc@0/bus@30000000/pinctrl@30330000/usdhc3-200mhzgrp";
		pinctrl_wdog = "/soc@0/bus@30000000/pinctrl@30330000/wdoggrp";
		gpr = "/soc@0/bus@30000000/syscon@30340000";
		ocotp = "/soc@0/bus@30000000/efuse@30350000";
		imx8mp_uid = "/soc@0/bus@30000000/efuse@30350000/unique-id@8";
		cpu_speed_grade = "/soc@0/bus@30000000/efuse@30350000/speed-grade@10";
		eth_mac1 = "/soc@0/bus@30000000/efuse@30350000/mac-address@90";
		eth_mac2 = "/soc@0/bus@30000000/efuse@30350000/mac-address@96";
		tmu_calib = "/soc@0/bus@30000000/efuse@30350000/calib@264";
		anatop = "/soc@0/bus@30000000/clock-controller@30360000";
		snvs = "/soc@0/bus@30000000/snvs@30370000";
		snvs_rtc = "/soc@0/bus@30000000/snvs@30370000/snvs-rtc-lp";
		snvs_pwrkey = "/soc@0/bus@30000000/snvs@30370000/snvs-powerkey";
		snvs_lpgpr = "/soc@0/bus@30000000/snvs@30370000/snvs-lpgpr";
		clk = "/soc@0/bus@30000000/clock-controller@30380000";
		src = "/soc@0/bus@30000000/reset-controller@30390000";
		gpc = "/soc@0/bus@30000000/gpc@303a0000";
		pgc_mipi_phy1 = "/soc@0/bus@30000000/gpc@303a0000/pgc/power-domain@0";
		pgc_pcie_phy = "/soc@0/bus@30000000/gpc@303a0000/pgc/power-domain@1";
		pgc_usb1_phy = "/soc@0/bus@30000000/gpc@303a0000/pgc/power-domain@2";
		pgc_usb2_phy = "/soc@0/bus@30000000/gpc@303a0000/pgc/power-domain@3";
		pgc_mlmix = "/soc@0/bus@30000000/gpc@303a0000/pgc/power-domain@4";
		pgc_audio = "/soc@0/bus@30000000/gpc@303a0000/pgc/power-domain@5";
		pgc_gpu2d = "/soc@0/bus@30000000/gpc@303a0000/pgc/power-domain@6";
		pgc_gpumix = "/soc@0/bus@30000000/gpc@303a0000/pgc/power-domain@7";
		pgc_vpumix = "/soc@0/bus@30000000/gpc@303a0000/pgc/power-domain@8";
		pgc_gpu3d = "/soc@0/bus@30000000/gpc@303a0000/pgc/power-domain@9";
		pgc_mediamix = "/soc@0/bus@30000000/gpc@303a0000/pgc/power-domain@10";
		pgc_vpu_g1 = "/soc@0/bus@30000000/gpc@303a0000/pgc/power-domain@11";
		pgc_vpu_g2 = "/soc@0/bus@30000000/gpc@303a0000/pgc/power-domain@12";
		pgc_vpu_vc8000e = "/soc@0/bus@30000000/gpc@303a0000/pgc/power-domain@13";
		pgc_hdmimix = "/soc@0/bus@30000000/gpc@303a0000/pgc/power-domain@14";
		pgc_hdmi_phy = "/soc@0/bus@30000000/gpc@303a0000/pgc/power-domain@15";
		pgc_mipi_phy2 = "/soc@0/bus@30000000/gpc@303a0000/pgc/power-domain@16";
		pgc_hsiomix = "/soc@0/bus@30000000/gpc@303a0000/pgc/power-domain@17";
		pgc_ispdwp = "/soc@0/bus@30000000/gpc@303a0000/pgc/power-domain@18";
		aips2 = "/soc@0/bus@30400000";
		pwm1 = "/soc@0/bus@30400000/pwm@30660000";
		pwm2 = "/soc@0/bus@30400000/pwm@30670000";
		pwm3 = "/soc@0/bus@30400000/pwm@30680000";
		pwm4 = "/soc@0/bus@30400000/pwm@30690000";
		system_counter = "/soc@0/bus@30400000/timer@306a0000";
		gpt6 = "/soc@0/bus@30400000/timer@306e0000";
		gpt5 = "/soc@0/bus@30400000/timer@306f0000";
		gpt4 = "/soc@0/bus@30400000/timer@30700000";
		aips3 = "/soc@0/bus@30800000";
		ecspi1 = "/soc@0/bus@30800000/spba-bus@30800000/spi@30820000";
		ecspi2 = "/soc@0/bus@30800000/spba-bus@30800000/spi@30830000";
		ecspi3 = "/soc@0/bus@30800000/spba-bus@30800000/spi@30840000";
		uart1 = "/soc@0/bus@30800000/spba-bus@30800000/serial@30860000";
		uart3 = "/soc@0/bus@30800000/spba-bus@30800000/serial@30880000";
		uart2 = "/soc@0/bus@30800000/spba-bus@30800000/serial@30890000";
		flexcan1 = "/soc@0/bus@30800000/spba-bus@30800000/can@308c0000";
		flexcan2 = "/soc@0/bus@30800000/spba-bus@30800000/can@308d0000";
		crypto = "/soc@0/bus@30800000/crypto@30900000";
		sec_jr0 = "/soc@0/bus@30800000/crypto@30900000/jr@1000";
		sec_jr1 = "/soc@0/bus@30800000/crypto@30900000/jr@2000";
		sec_jr2 = "/soc@0/bus@30800000/crypto@30900000/jr@3000";
		i2c1 = "/soc@0/bus@30800000/i2c@30a20000";
		reg_arm = "/soc@0/bus@30800000/i2c@30a20000/pmic@25/regulators/BUCK2";
		reg_buck5 = "/soc@0/bus@30800000/i2c@30a20000/pmic@25/regulators/BUCK5";
		i2c2 = "/soc@0/bus@30800000/i2c@30a30000";
		adv7535_in = "/soc@0/bus@30800000/i2c@30a30000/hdmi@3d/ports/port@0/endpoint";
		adv7535_out = "/soc@0/bus@30800000/i2c@30a30000/hdmi@3d/ports/port@1/endpoint";
		i2c3 = "/soc@0/bus@30800000/i2c@30a40000";
		wm8960 = "/soc@0/bus@30800000/i2c@30a40000/codec@1a";
		pca6416 = "/soc@0/bus@30800000/i2c@30a40000/gpio@20";
		i2c4 = "/soc@0/bus@30800000/i2c@30a50000";
		uart4 = "/soc@0/bus@30800000/serial@30a60000";
		mu = "/soc@0/bus@30800000/mailbox@30aa0000";
		mu2 = "/soc@0/bus@30800000/mailbox@30e60000";
		i2c5 = "/soc@0/bus@30800000/i2c@30ad0000";
		i2c6 = "/soc@0/bus@30800000/i2c@30ae0000";
		usdhc1 = "/soc@0/bus@30800000/mmc@30b40000";
		usdhc2 = "/soc@0/bus@30800000/mmc@30b50000";
		usdhc3 = "/soc@0/bus@30800000/mmc@30b60000";
		flexspi = "/soc@0/bus@30800000/spi@30bb0000";
		sdma1 = "/soc@0/bus@30800000/dma-controller@30bd0000";
		fec = "/soc@0/bus@30800000/ethernet@30be0000";
		ethphy1 = "/soc@0/bus@30800000/ethernet@30be0000/mdio/ethernet-phy@1";
		eqos = "/soc@0/bus@30800000/ethernet@30bf0000";
		ethphy0 = "/soc@0/bus@30800000/ethernet@30bf0000/mdio/ethernet-phy@1";
		mtl_tx_setup = "/soc@0/bus@30800000/ethernet@30bf0000/tx-queues-config";
		mtl_rx_setup = "/soc@0/bus@30800000/ethernet@30bf0000/rx-queues-config";
		aips5 = "/soc@0/bus@30c00000";
		sai1 = "/soc@0/bus@30c00000/spba-bus@30c00000/sai@30c10000";
		sai2 = "/soc@0/bus@30c00000/spba-bus@30c00000/sai@30c20000";
		sai3 = "/soc@0/bus@30c00000/spba-bus@30c00000/sai@30c30000";
		sai5 = "/soc@0/bus@30c00000/spba-bus@30c00000/sai@30c50000";
		sai6 = "/soc@0/bus@30c00000/spba-bus@30c00000/sai@30c60000";
		sai7 = "/soc@0/bus@30c00000/spba-bus@30c00000/sai@30c80000";
		easrc = "/soc@0/bus@30c00000/spba-bus@30c00000/easrc@30c90000";
		micfil = "/soc@0/bus@30c00000/spba-bus@30c00000/audio-controller@30ca0000";
		aud2htx = "/soc@0/bus@30c00000/spba-bus@30c00000/aud2htx@30cb0000";
		xcvr = "/soc@0/bus@30c00000/spba-bus@30c00000/xcvr@30cc0000";
		sdma3 = "/soc@0/bus@30c00000/dma-controller@30e00000";
		sdma2 = "/soc@0/bus@30c00000/dma-controller@30e10000";
		audio_blk_ctrl = "/soc@0/bus@30c00000/clock-controller@30e20000";
		noc = "/soc@0/interconnect@32700000";
		noc_opp_table = "/soc@0/interconnect@32700000/opp-table";
		aips4 = "/soc@0/bus@32c00000";
		isi_0 = "/soc@0/bus@32c00000/isi@32e00000";
		isi_in_0 = "/soc@0/bus@32c00000/isi@32e00000/ports/port@0/endpoint";
		isi_in_1 = "/soc@0/bus@32c00000/isi@32e00000/ports/port@1/endpoint";
		dewarp = "/soc@0/bus@32c00000/dwe@32e30000";
		mipi_csi_0 = "/soc@0/bus@32c00000/csi@32e40000";
		mipi_csi_0_out = "/soc@0/bus@32c00000/csi@32e40000/ports/port@1/endpoint";
		mipi_csi_1 = "/soc@0/bus@32c00000/csi@32e50000";
		mipi_csi_1_out = "/soc@0/bus@32c00000/csi@32e50000/ports/port@1/endpoint";
		mipi_dsi = "/soc@0/bus@32c00000/dsi@32e60000";
		dsim_from_lcdif1 = "/soc@0/bus@32c00000/dsi@32e60000/ports/port@0/endpoint";
		dsi_out = "/soc@0/bus@32c00000/dsi@32e60000/ports/port@1/endpoint";
		mipi_dsi_out = "/soc@0/bus@32c00000/dsi@32e60000/ports/port@1/endpoint";
		lcdif1 = "/soc@0/bus@32c00000/display-controller@32e80000";
		lcdif1_to_dsim = "/soc@0/bus@32c00000/display-controller@32e80000/port/endpoint";
		lcdif2 = "/soc@0/bus@32c00000/display-controller@32e90000";
		lcdif2_to_ldb = "/soc@0/bus@32c00000/display-controller@32e90000/port/endpoint";
		media_blk_ctrl = "/soc@0/bus@32c00000/blk-ctrl@32ec0000";
		lvds_bridge = "/soc@0/bus@32c00000/blk-ctrl@32ec0000/bridge@5c";
		ldb_from_lcdif2 = "/soc@0/bus@32c00000/blk-ctrl@32ec0000/bridge@5c/ports/port@0/endpoint";
		ldb_lvds_ch0 = "/soc@0/bus@32c00000/blk-ctrl@32ec0000/bridge@5c/ports/port@1/endpoint";
		ldb_lvds_ch1 = "/soc@0/bus@32c00000/blk-ctrl@32ec0000/bridge@5c/ports/port@2/endpoint";
		pcie_phy = "/soc@0/bus@32c00000/pcie-phy@32f00000";
		hsio_blk_ctrl = "/soc@0/bus@32c00000/blk-ctrl@32f10000";
		hdmi_blk_ctrl = "/soc@0/bus@32c00000/blk-ctrl@32fc0000";
		irqsteer_hdmi = "/soc@0/bus@32c00000/interrupt-controller@32fc2000";
		hdmi_pvi = "/soc@0/bus@32c00000/display-bridge@32fc4000";
		pvi_from_lcdif3 = "/soc@0/bus@32c00000/display-bridge@32fc4000/ports/port@0/endpoint";
		pvi_to_hdmi_tx = "/soc@0/bus@32c00000/display-bridge@32fc4000/ports/port@1/endpoint";
		lcdif3 = "/soc@0/bus@32c00000/display-controller@32fc6000";
		lcdif3_to_pvi = "/soc@0/bus@32c00000/display-controller@32fc6000/port/endpoint";
		hdmi_tx = "/soc@0/bus@32c00000/hdmi@32fd8000";
		hdmi_tx_from_pvi = "/soc@0/bus@32c00000/hdmi@32fd8000/ports/port@0/endpoint";
		hdmi_tx_phy = "/soc@0/bus@32c00000/phy@32fdff00";
		pcie = "/soc@0/pcie@33800000";
		pcie_ep = "/soc@0/pcie-ep@33800000";
		gpu3d = "/soc@0/gpu@38000000";
		gpu2d = "/soc@0/gpu@38008000";
		vpu_g1 = "/soc@0/video-codec@38300000";
		vpu_g2 = "/soc@0/video-codec@38310000";
		vpumix_blk_ctrl = "/soc@0/blk-ctrl@38330000";
		npu = "/soc@0/npu@38500000";
		gic = "/soc@0/interrupt-controller@38800000";
		edacmc = "/soc@0/memory-controller@3d400000";
		usb3_phy0 = "/soc@0/usb-phy@381f0040";
		usb3_0 = "/soc@0/usb@32f10100";
		usb_dwc3_0 = "/soc@0/usb@32f10100/usb@38100000";
		usb3_phy1 = "/soc@0/usb-phy@382f0040";
		usb3_1 = "/soc@0/usb@32f10108";
		usb_dwc3_1 = "/soc@0/usb@32f10108/usb@38200000";
		dsp = "/soc@0/dsp@3b6e8000";
		backlight_lvds = "/backlight-lvds";
		hdmi_connector_in = "/hdmi-connector/port/endpoint";
		pcie0_refclk = "/pcie0-refclk";
		reg_audio_pwr = "/regulator-audio-pwr";
		reg_can1_stby = "/regulator-can1-stby";
		reg_can2_stby = "/regulator-can2-stby";
		reg_pcie0 = "/regulator-pcie";
		reg_per_12v = "/regulator-per-12v";
		reg_usdhc2_vmmc = "/regulator-usdhc2";
		reg_vext_3v3 = "/regulator-vext-3v3";
		audio_codec_bt_sco = "/audio-codec-bt-sco";
		cpudai = "/sound/simple-audio-card,cpu";
		btcpu = "/sound-bt-sco/simple-audio-card,cpu";
	};
};
